# sam67_dmpac_wrap0_DMPAC_TOP_CFG_SLV_CP_INTD_CFG_INTD_CFG register map
Vendor: Texas Instruments
Peripheral module from a debugger description file (folder J722S).
Registers are 32-bit, access not given, reset 0x0 unless marked. A register's access mark holds for its fields unless they carry their own. Offsets are as the file gives them; lines under a group give offsets from that group; [hi:lo] are bit positions; {n}, {i} and the like mark numbered series; 'fields as' and 'values as' point back to an identical list; <NAME> marks a mode.

## sam67_dmpac_wrap0_DMPAC_TOP_CFG_SLV_CP_INTD_CFG_INTD_CFG (part 1 of 2)
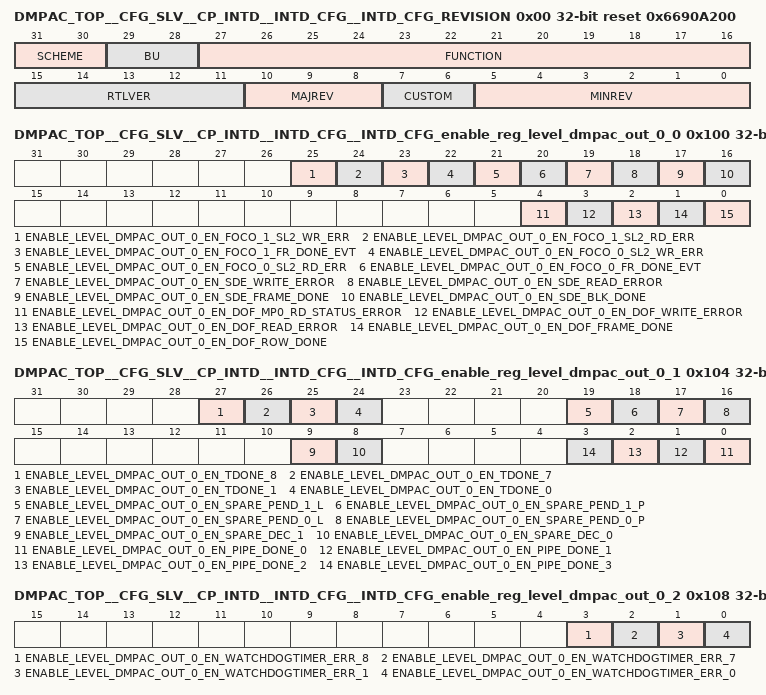
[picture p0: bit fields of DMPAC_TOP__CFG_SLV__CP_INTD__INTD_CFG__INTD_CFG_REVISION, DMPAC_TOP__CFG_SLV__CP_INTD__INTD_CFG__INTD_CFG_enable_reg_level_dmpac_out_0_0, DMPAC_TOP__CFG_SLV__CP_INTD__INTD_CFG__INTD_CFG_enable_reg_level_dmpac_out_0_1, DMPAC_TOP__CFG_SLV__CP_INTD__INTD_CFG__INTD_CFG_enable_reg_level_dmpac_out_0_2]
0x00 DMPAC_TOP__CFG_SLV__CP_INTD__INTD_CFG__INTD_CFG_REVISION ro reset 0x6690A200 — Revision Register
  [31:30] SCHEME
  [29:28] BU
  [27:16] FUNCTION — Module ID
  [15:11] RTLVER — RTL revisions
  [10:8] MAJREV — Major revision
  [7:6] CUSTOM — Custom revision
  [5:0] MINREV — Minor revision
0x10 DMPAC_TOP__CFG_SLV__CP_INTD__INTD_CFG__INTD_CFG_eoi_reg rw — End of Interrupt Register
  [7:0] EOI_VECTOR — End of Interrupt Vector
0x14 DMPAC_TOP__CFG_SLV__CP_INTD__INTD_CFG__INTD_CFG_intr_vector_reg ro — Interrupt Vector Register
  [31:0] INTR_VECTOR
0x100 DMPAC_TOP__CFG_SLV__CP_INTD__INTD_CFG__INTD_CFG_enable_reg_level_dmpac_out_0_0 — Enable Register 0
  [25] ENABLE_LEVEL_DMPAC_OUT_0_EN_FOCO_1_SL2_WR_ERR — Enable Set for level_dmpac_out_0_en_foco_1_sl2_wr_err (access R/W1TS)
  [24] ENABLE_LEVEL_DMPAC_OUT_0_EN_FOCO_1_SL2_RD_ERR — Enable Set for level_dmpac_out_0_en_foco_1_sl2_rd_err (access R/W1TS)
  [23] ENABLE_LEVEL_DMPAC_OUT_0_EN_FOCO_1_FR_DONE_EVT — Enable Set for level_dmpac_out_0_en_foco_1_fr_done_evt (access R/W1TS)
  [22] ENABLE_LEVEL_DMPAC_OUT_0_EN_FOCO_0_SL2_WR_ERR — Enable Set for level_dmpac_out_0_en_foco_0_sl2_wr_err (access R/W1TS)
  [21] ENABLE_LEVEL_DMPAC_OUT_0_EN_FOCO_0_SL2_RD_ERR — Enable Set for level_dmpac_out_0_en_foco_0_sl2_rd_err (access R/W1TS)
  [20] ENABLE_LEVEL_DMPAC_OUT_0_EN_FOCO_0_FR_DONE_EVT — Enable Set for level_dmpac_out_0_en_foco_0_fr_done_evt (access R/W1TS)
  [19] ENABLE_LEVEL_DMPAC_OUT_0_EN_SDE_WRITE_ERROR — Enable Set for level_dmpac_out_0_en_sde_write_error (access R/W1TS)
  [18] ENABLE_LEVEL_DMPAC_OUT_0_EN_SDE_READ_ERROR — Enable Set for level_dmpac_out_0_en_sde_read_error (access R/W1TS)
  [17] ENABLE_LEVEL_DMPAC_OUT_0_EN_SDE_FRAME_DONE — Enable Set for level_dmpac_out_0_en_sde_frame_done (access R/W1TS)
  [16] ENABLE_LEVEL_DMPAC_OUT_0_EN_SDE_BLK_DONE — Enable Set for level_dmpac_out_0_en_sde_blk_done (access R/W1TS)
  [4] ENABLE_LEVEL_DMPAC_OUT_0_EN_DOF_MP0_RD_STATUS_ERROR — Enable Set for level_dmpac_out_0_en_dof_mp0_rd_status_error (access R/W1TS)
  [3] ENABLE_LEVEL_DMPAC_OUT_0_EN_DOF_WRITE_ERROR — Enable Set for level_dmpac_out_0_en_dof_write_error (access R/W1TS)
  [2] ENABLE_LEVEL_DMPAC_OUT_0_EN_DOF_READ_ERROR — Enable Set for level_dmpac_out_0_en_dof_read_error (access R/W1TS)
  [1] ENABLE_LEVEL_DMPAC_OUT_0_EN_DOF_FRAME_DONE — Enable Set for level_dmpac_out_0_en_dof_frame_done (access R/W1TS)
  [0] ENABLE_LEVEL_DMPAC_OUT_0_EN_DOF_ROW_DONE — Enable Set for level_dmpac_out_0_en_dof_row_done (access R/W1TS)
0x104 DMPAC_TOP__CFG_SLV__CP_INTD__INTD_CFG__INTD_CFG_enable_reg_level_dmpac_out_0_1 — Enable Register 1
  [27] ENABLE_LEVEL_DMPAC_OUT_0_EN_TDONE_8 — Enable Set for level_dmpac_out_0_en_tdone_8 (access R/W1TS)
  [26] ENABLE_LEVEL_DMPAC_OUT_0_EN_TDONE_7 — Enable Set for level_dmpac_out_0_en_tdone_7 (access R/W1TS)
  [25] ENABLE_LEVEL_DMPAC_OUT_0_EN_TDONE_1 — Enable Set for level_dmpac_out_0_en_tdone_1 (access R/W1TS)
  [24] ENABLE_LEVEL_DMPAC_OUT_0_EN_TDONE_0 — Enable Set for level_dmpac_out_0_en_tdone_0 (access R/W1TS)
  [19] ENABLE_LEVEL_DMPAC_OUT_0_EN_SPARE_PEND_1_L — Enable Set for level_dmpac_out_0_en_spare_pend_1_l (access R/W1TS)
  [18] ENABLE_LEVEL_DMPAC_OUT_0_EN_SPARE_PEND_1_P — Enable Set for level_dmpac_out_0_en_spare_pend_1_p (access R/W1TS)
  [17] ENABLE_LEVEL_DMPAC_OUT_0_EN_SPARE_PEND_0_L — Enable Set for level_dmpac_out_0_en_spare_pend_0_l (access R/W1TS)
  [16] ENABLE_LEVEL_DMPAC_OUT_0_EN_SPARE_PEND_0_P — Enable Set for level_dmpac_out_0_en_spare_pend_0_p (access R/W1TS)
  [9] ENABLE_LEVEL_DMPAC_OUT_0_EN_SPARE_DEC_1 — Enable Set for level_dmpac_out_0_en_spare_dec_1 (access R/W1TS)
  [8] ENABLE_LEVEL_DMPAC_OUT_0_EN_SPARE_DEC_0 — Enable Set for level_dmpac_out_0_en_spare_dec_0 (access R/W1TS)
  [n] ENABLE_LEVEL_DMPAC_OUT_0_EN_PIPE_DONE_{n} (n=0..3) — Enable Set for level_dmpac_out_0_en_pipe_done_{n} (access R/W1TS)
0x108 DMPAC_TOP__CFG_SLV__CP_INTD__INTD_CFG__INTD_CFG_enable_reg_level_dmpac_out_0_2 — Enable Register 2
  [3] ENABLE_LEVEL_DMPAC_OUT_0_EN_WATCHDOGTIMER_ERR_8 — Enable Set for level_dmpac_out_0_en_watchdogtimer_err_8 (access R/W1TS)
  [2] ENABLE_LEVEL_DMPAC_OUT_0_EN_WATCHDOGTIMER_ERR_7 — Enable Set for level_dmpac_out_0_en_watchdogtimer_err_7 (access R/W1TS)
  [1] ENABLE_LEVEL_DMPAC_OUT_0_EN_WATCHDOGTIMER_ERR_1 — Enable Set for level_dmpac_out_0_en_watchdogtimer_err_1 (access R/W1TS)
  [0] ENABLE_LEVEL_DMPAC_OUT_0_EN_WATCHDOGTIMER_ERR_0 — Enable Set for level_dmpac_out_0_en_watchdogtimer_err_0 (access R/W1TS)
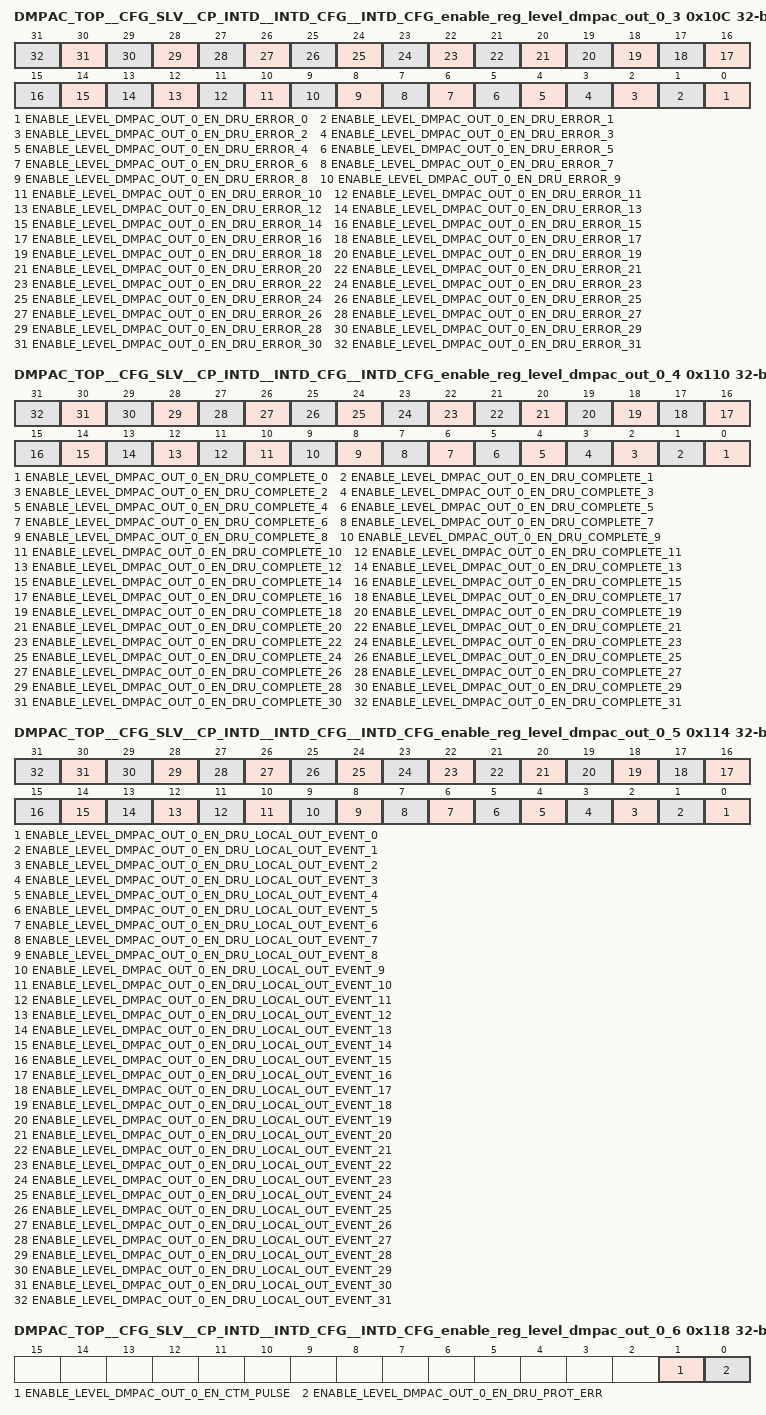
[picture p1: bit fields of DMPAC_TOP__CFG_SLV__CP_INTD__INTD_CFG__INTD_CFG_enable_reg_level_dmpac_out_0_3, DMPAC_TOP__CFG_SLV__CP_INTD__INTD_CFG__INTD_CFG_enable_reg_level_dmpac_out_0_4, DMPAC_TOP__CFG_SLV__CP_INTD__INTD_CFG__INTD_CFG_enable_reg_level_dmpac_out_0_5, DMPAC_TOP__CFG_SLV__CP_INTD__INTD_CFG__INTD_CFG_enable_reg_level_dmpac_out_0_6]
0x10C DMPAC_TOP__CFG_SLV__CP_INTD__INTD_CFG__INTD_CFG_enable_reg_level_dmpac_out_0_3 — Enable Register 3
  [n] ENABLE_LEVEL_DMPAC_OUT_0_EN_DRU_ERROR_{n} (n=0..31) — Enable Set for level_dmpac_out_0_en_dru_error_{n} (access R/W1TS)
0x110 DMPAC_TOP__CFG_SLV__CP_INTD__INTD_CFG__INTD_CFG_enable_reg_level_dmpac_out_0_4 — Enable Register 4
  [n] ENABLE_LEVEL_DMPAC_OUT_0_EN_DRU_COMPLETE_{n} (n=0..31) — Enable Set for level_dmpac_out_0_en_dru_complete_{n} (access R/W1TS)
0x114 DMPAC_TOP__CFG_SLV__CP_INTD__INTD_CFG__INTD_CFG_enable_reg_level_dmpac_out_0_5 — Enable Register 5
  [n] ENABLE_LEVEL_DMPAC_OUT_0_EN_DRU_LOCAL_OUT_EVENT_{n} (n=0..31) — Enable Set for level_dmpac_out_0_en_dru_local_out_event_{n} (access R/W1TS)
0x118 DMPAC_TOP__CFG_SLV__CP_INTD__INTD_CFG__INTD_CFG_enable_reg_level_dmpac_out_0_6 — Enable Register 6
  [1] ENABLE_LEVEL_DMPAC_OUT_0_EN_CTM_PULSE — Enable Set for level_dmpac_out_0_en_ctm_pulse (access R/W1TS)
  [0] ENABLE_LEVEL_DMPAC_OUT_0_EN_DRU_PROT_ERR — Enable Set for level_dmpac_out_0_en_dru_prot_err (access R/W1TS)
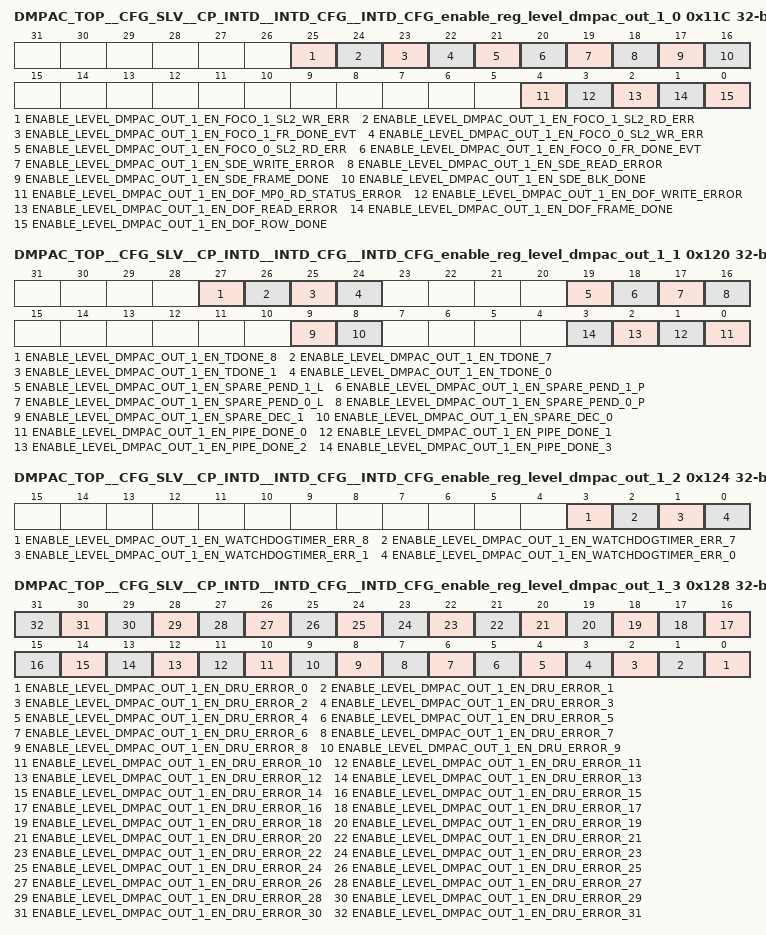
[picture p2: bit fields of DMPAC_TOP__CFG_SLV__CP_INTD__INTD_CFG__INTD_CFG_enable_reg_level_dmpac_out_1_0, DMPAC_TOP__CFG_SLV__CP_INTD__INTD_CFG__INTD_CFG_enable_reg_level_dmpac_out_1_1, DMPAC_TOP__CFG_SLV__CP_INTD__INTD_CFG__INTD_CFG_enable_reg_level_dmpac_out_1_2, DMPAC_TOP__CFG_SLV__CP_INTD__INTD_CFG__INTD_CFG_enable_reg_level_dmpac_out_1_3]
0x11C DMPAC_TOP__CFG_SLV__CP_INTD__INTD_CFG__INTD_CFG_enable_reg_level_dmpac_out_1_0 — Enable Register 7
  [25] ENABLE_LEVEL_DMPAC_OUT_1_EN_FOCO_1_SL2_WR_ERR — Enable Set for level_dmpac_out_1_en_foco_1_sl2_wr_err (access R/W1TS)
  [24] ENABLE_LEVEL_DMPAC_OUT_1_EN_FOCO_1_SL2_RD_ERR — Enable Set for level_dmpac_out_1_en_foco_1_sl2_rd_err (access R/W1TS)
  [23] ENABLE_LEVEL_DMPAC_OUT_1_EN_FOCO_1_FR_DONE_EVT — Enable Set for level_dmpac_out_1_en_foco_1_fr_done_evt (access R/W1TS)
  [22] ENABLE_LEVEL_DMPAC_OUT_1_EN_FOCO_0_SL2_WR_ERR — Enable Set for level_dmpac_out_1_en_foco_0_sl2_wr_err (access R/W1TS)
  [21] ENABLE_LEVEL_DMPAC_OUT_1_EN_FOCO_0_SL2_RD_ERR — Enable Set for level_dmpac_out_1_en_foco_0_sl2_rd_err (access R/W1TS)
  [20] ENABLE_LEVEL_DMPAC_OUT_1_EN_FOCO_0_FR_DONE_EVT — Enable Set for level_dmpac_out_1_en_foco_0_fr_done_evt (access R/W1TS)
  [19] ENABLE_LEVEL_DMPAC_OUT_1_EN_SDE_WRITE_ERROR — Enable Set for level_dmpac_out_1_en_sde_write_error (access R/W1TS)
  [18] ENABLE_LEVEL_DMPAC_OUT_1_EN_SDE_READ_ERROR — Enable Set for level_dmpac_out_1_en_sde_read_error (access R/W1TS)
  [17] ENABLE_LEVEL_DMPAC_OUT_1_EN_SDE_FRAME_DONE — Enable Set for level_dmpac_out_1_en_sde_frame_done (access R/W1TS)
  [16] ENABLE_LEVEL_DMPAC_OUT_1_EN_SDE_BLK_DONE — Enable Set for level_dmpac_out_1_en_sde_blk_done (access R/W1TS)
  [4] ENABLE_LEVEL_DMPAC_OUT_1_EN_DOF_MP0_RD_STATUS_ERROR — Enable Set for level_dmpac_out_1_en_dof_mp0_rd_status_error (access R/W1TS)
  [3] ENABLE_LEVEL_DMPAC_OUT_1_EN_DOF_WRITE_ERROR — Enable Set for level_dmpac_out_1_en_dof_write_error (access R/W1TS)
  [2] ENABLE_LEVEL_DMPAC_OUT_1_EN_DOF_READ_ERROR — Enable Set for level_dmpac_out_1_en_dof_read_error (access R/W1TS)
  [1] ENABLE_LEVEL_DMPAC_OUT_1_EN_DOF_FRAME_DONE — Enable Set for level_dmpac_out_1_en_dof_frame_done (access R/W1TS)
  [0] ENABLE_LEVEL_DMPAC_OUT_1_EN_DOF_ROW_DONE — Enable Set for level_dmpac_out_1_en_dof_row_done (access R/W1TS)
0x120 DMPAC_TOP__CFG_SLV__CP_INTD__INTD_CFG__INTD_CFG_enable_reg_level_dmpac_out_1_1 — Enable Register 8
  [27] ENABLE_LEVEL_DMPAC_OUT_1_EN_TDONE_8 — Enable Set for level_dmpac_out_1_en_tdone_8 (access R/W1TS)
  [26] ENABLE_LEVEL_DMPAC_OUT_1_EN_TDONE_7 — Enable Set for level_dmpac_out_1_en_tdone_7 (access R/W1TS)
  [25] ENABLE_LEVEL_DMPAC_OUT_1_EN_TDONE_1 — Enable Set for level_dmpac_out_1_en_tdone_1 (access R/W1TS)
  [24] ENABLE_LEVEL_DMPAC_OUT_1_EN_TDONE_0 — Enable Set for level_dmpac_out_1_en_tdone_0 (access R/W1TS)
  [19] ENABLE_LEVEL_DMPAC_OUT_1_EN_SPARE_PEND_1_L — Enable Set for level_dmpac_out_1_en_spare_pend_1_l (access R/W1TS)
  [18] ENABLE_LEVEL_DMPAC_OUT_1_EN_SPARE_PEND_1_P — Enable Set for level_dmpac_out_1_en_spare_pend_1_p (access R/W1TS)
  [17] ENABLE_LEVEL_DMPAC_OUT_1_EN_SPARE_PEND_0_L — Enable Set for level_dmpac_out_1_en_spare_pend_0_l (access R/W1TS)
  [16] ENABLE_LEVEL_DMPAC_OUT_1_EN_SPARE_PEND_0_P — Enable Set for level_dmpac_out_1_en_spare_pend_0_p (access R/W1TS)
  [9] ENABLE_LEVEL_DMPAC_OUT_1_EN_SPARE_DEC_1 — Enable Set for level_dmpac_out_1_en_spare_dec_1 (access R/W1TS)
  [8] ENABLE_LEVEL_DMPAC_OUT_1_EN_SPARE_DEC_0 — Enable Set for level_dmpac_out_1_en_spare_dec_0 (access R/W1TS)
  [n] ENABLE_LEVEL_DMPAC_OUT_1_EN_PIPE_DONE_{n} (n=0..3) — Enable Set for level_dmpac_out_1_en_pipe_done_{n} (access R/W1TS)
0x124 DMPAC_TOP__CFG_SLV__CP_INTD__INTD_CFG__INTD_CFG_enable_reg_level_dmpac_out_1_2 — Enable Register 9
  [3] ENABLE_LEVEL_DMPAC_OUT_1_EN_WATCHDOGTIMER_ERR_8 — Enable Set for level_dmpac_out_1_en_watchdogtimer_err_8 (access R/W1TS)
  [2] ENABLE_LEVEL_DMPAC_OUT_1_EN_WATCHDOGTIMER_ERR_7 — Enable Set for level_dmpac_out_1_en_watchdogtimer_err_7 (access R/W1TS)
  [1] ENABLE_LEVEL_DMPAC_OUT_1_EN_WATCHDOGTIMER_ERR_1 — Enable Set for level_dmpac_out_1_en_watchdogtimer_err_1 (access R/W1TS)
  [0] ENABLE_LEVEL_DMPAC_OUT_1_EN_WATCHDOGTIMER_ERR_0 — Enable Set for level_dmpac_out_1_en_watchdogtimer_err_0 (access R/W1TS)
0x128 DMPAC_TOP__CFG_SLV__CP_INTD__INTD_CFG__INTD_CFG_enable_reg_level_dmpac_out_1_3 — Enable Register 10
  [n] ENABLE_LEVEL_DMPAC_OUT_1_EN_DRU_ERROR_{n} (n=0..31) — Enable Set for level_dmpac_out_1_en_dru_error_{n} (access R/W1TS)
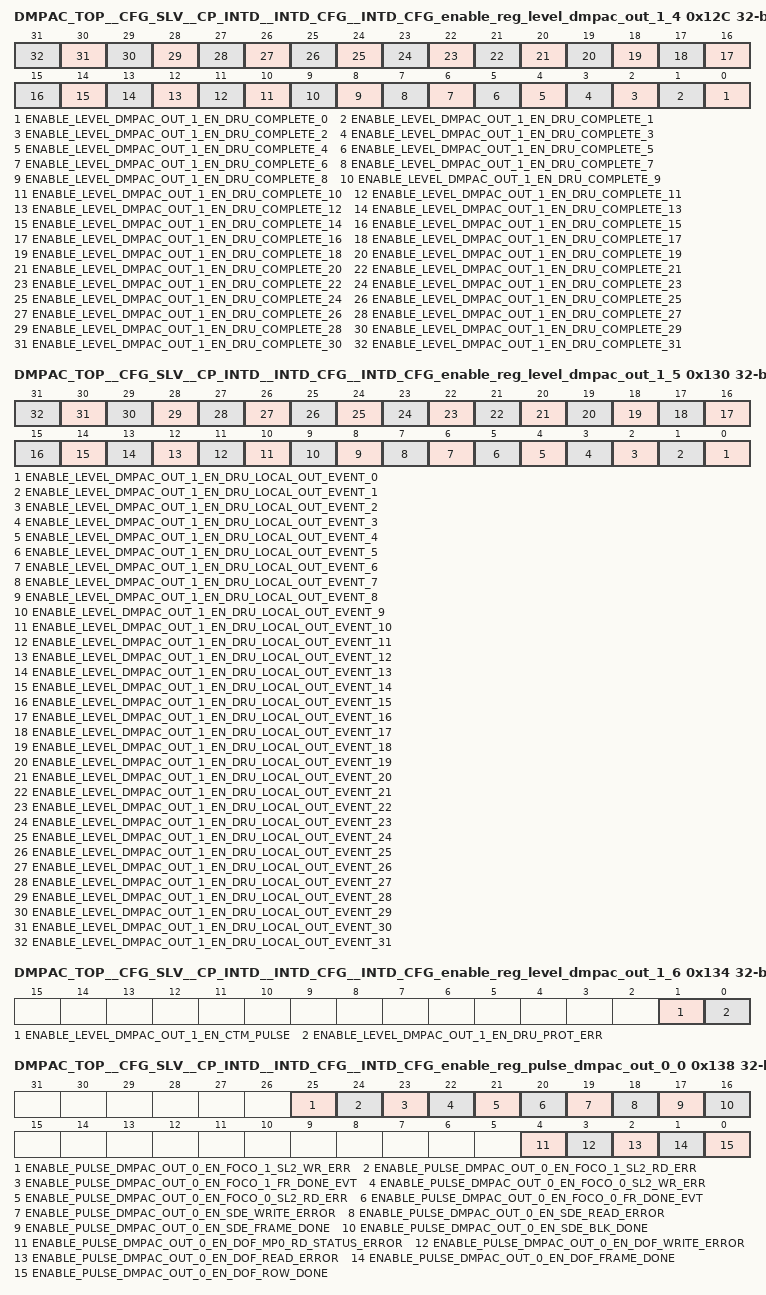
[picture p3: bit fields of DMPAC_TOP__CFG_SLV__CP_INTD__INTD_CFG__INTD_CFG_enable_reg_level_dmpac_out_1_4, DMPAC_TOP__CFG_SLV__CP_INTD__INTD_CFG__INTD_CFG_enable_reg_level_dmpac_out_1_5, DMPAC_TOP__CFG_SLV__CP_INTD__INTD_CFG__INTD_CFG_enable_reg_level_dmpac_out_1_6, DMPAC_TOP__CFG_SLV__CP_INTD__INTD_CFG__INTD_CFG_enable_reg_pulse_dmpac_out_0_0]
0x12C DMPAC_TOP__CFG_SLV__CP_INTD__INTD_CFG__INTD_CFG_enable_reg_level_dmpac_out_1_4 — Enable Register 11
  [n] ENABLE_LEVEL_DMPAC_OUT_1_EN_DRU_COMPLETE_{n} (n=0..31) — Enable Set for level_dmpac_out_1_en_dru_complete_{n} (access R/W1TS)
0x130 DMPAC_TOP__CFG_SLV__CP_INTD__INTD_CFG__INTD_CFG_enable_reg_level_dmpac_out_1_5 — Enable Register 12
  [n] ENABLE_LEVEL_DMPAC_OUT_1_EN_DRU_LOCAL_OUT_EVENT_{n} (n=0..31) — Enable Set for level_dmpac_out_1_en_dru_local_out_event_{n} (access R/W1TS)
0x134 DMPAC_TOP__CFG_SLV__CP_INTD__INTD_CFG__INTD_CFG_enable_reg_level_dmpac_out_1_6 — Enable Register 13
  [1] ENABLE_LEVEL_DMPAC_OUT_1_EN_CTM_PULSE — Enable Set for level_dmpac_out_1_en_ctm_pulse (access R/W1TS)
  [0] ENABLE_LEVEL_DMPAC_OUT_1_EN_DRU_PROT_ERR — Enable Set for level_dmpac_out_1_en_dru_prot_err (access R/W1TS)
0x138 DMPAC_TOP__CFG_SLV__CP_INTD__INTD_CFG__INTD_CFG_enable_reg_pulse_dmpac_out_0_0 — Enable Register 14
  [25] ENABLE_PULSE_DMPAC_OUT_0_EN_FOCO_1_SL2_WR_ERR — Enable Set for pulse_dmpac_out_0_en_foco_1_sl2_wr_err (access R/W1TS)
  [24] ENABLE_PULSE_DMPAC_OUT_0_EN_FOCO_1_SL2_RD_ERR — Enable Set for pulse_dmpac_out_0_en_foco_1_sl2_rd_err (access R/W1TS)
  [23] ENABLE_PULSE_DMPAC_OUT_0_EN_FOCO_1_FR_DONE_EVT — Enable Set for pulse_dmpac_out_0_en_foco_1_fr_done_evt (access R/W1TS)
  [22] ENABLE_PULSE_DMPAC_OUT_0_EN_FOCO_0_SL2_WR_ERR — Enable Set for pulse_dmpac_out_0_en_foco_0_sl2_wr_err (access R/W1TS)
  [21] ENABLE_PULSE_DMPAC_OUT_0_EN_FOCO_0_SL2_RD_ERR — Enable Set for pulse_dmpac_out_0_en_foco_0_sl2_rd_err (access R/W1TS)
  [20] ENABLE_PULSE_DMPAC_OUT_0_EN_FOCO_0_FR_DONE_EVT — Enable Set for pulse_dmpac_out_0_en_foco_0_fr_done_evt (access R/W1TS)
  [19] ENABLE_PULSE_DMPAC_OUT_0_EN_SDE_WRITE_ERROR — Enable Set for pulse_dmpac_out_0_en_sde_write_error (access R/W1TS)
  [18] ENABLE_PULSE_DMPAC_OUT_0_EN_SDE_READ_ERROR — Enable Set for pulse_dmpac_out_0_en_sde_read_error (access R/W1TS)
  [17] ENABLE_PULSE_DMPAC_OUT_0_EN_SDE_FRAME_DONE — Enable Set for pulse_dmpac_out_0_en_sde_frame_done (access R/W1TS)
  [16] ENABLE_PULSE_DMPAC_OUT_0_EN_SDE_BLK_DONE — Enable Set for pulse_dmpac_out_0_en_sde_blk_done (access R/W1TS)
  [4] ENABLE_PULSE_DMPAC_OUT_0_EN_DOF_MP0_RD_STATUS_ERROR — Enable Set for pulse_dmpac_out_0_en_dof_mp0_rd_status_error (access R/W1TS)
  [3] ENABLE_PULSE_DMPAC_OUT_0_EN_DOF_WRITE_ERROR — Enable Set for pulse_dmpac_out_0_en_dof_write_error (access R/W1TS)
  [2] ENABLE_PULSE_DMPAC_OUT_0_EN_DOF_READ_ERROR — Enable Set for pulse_dmpac_out_0_en_dof_read_error (access R/W1TS)
  [1] ENABLE_PULSE_DMPAC_OUT_0_EN_DOF_FRAME_DONE — Enable Set for pulse_dmpac_out_0_en_dof_frame_done (access R/W1TS)
  [0] ENABLE_PULSE_DMPAC_OUT_0_EN_DOF_ROW_DONE — Enable Set for pulse_dmpac_out_0_en_dof_row_done (access R/W1TS)
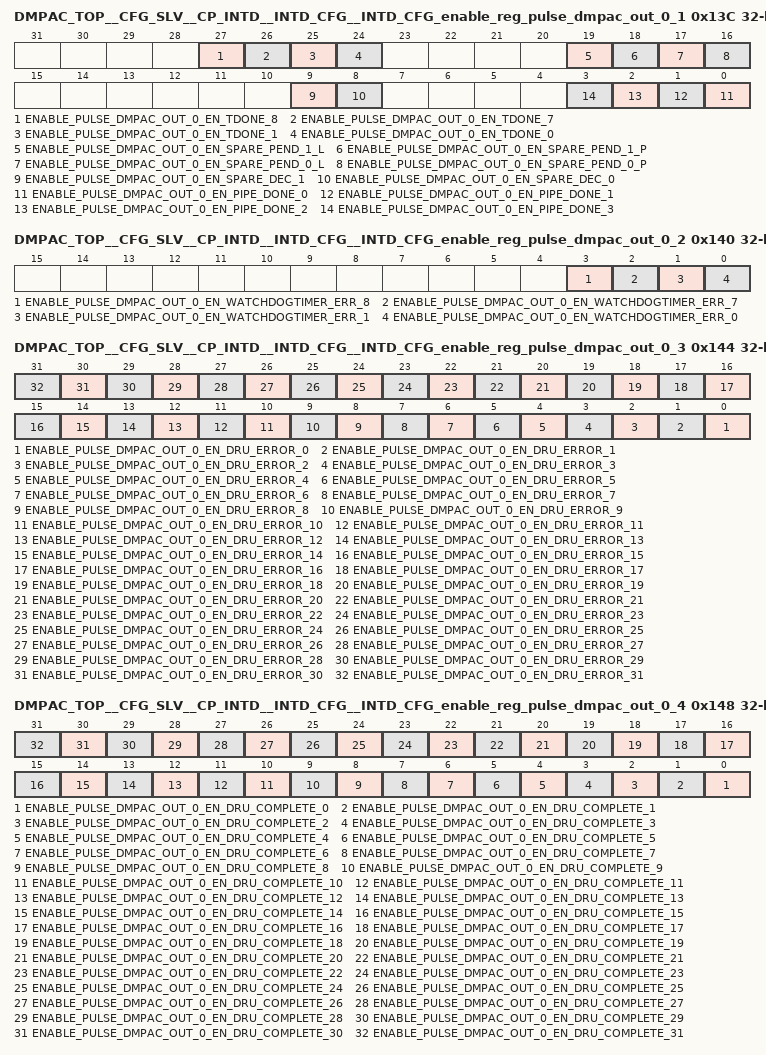
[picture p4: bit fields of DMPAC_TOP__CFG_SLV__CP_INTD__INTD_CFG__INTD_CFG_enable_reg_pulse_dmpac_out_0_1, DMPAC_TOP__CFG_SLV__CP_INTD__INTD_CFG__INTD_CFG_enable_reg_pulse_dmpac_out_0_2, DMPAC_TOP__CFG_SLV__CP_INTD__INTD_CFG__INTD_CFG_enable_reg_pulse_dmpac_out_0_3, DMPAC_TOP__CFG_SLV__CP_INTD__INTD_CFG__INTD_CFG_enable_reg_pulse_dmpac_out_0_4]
0x13C DMPAC_TOP__CFG_SLV__CP_INTD__INTD_CFG__INTD_CFG_enable_reg_pulse_dmpac_out_0_1 — Enable Register 15
  [27] ENABLE_PULSE_DMPAC_OUT_0_EN_TDONE_8 — Enable Set for pulse_dmpac_out_0_en_tdone_8 (access R/W1TS)
  [26] ENABLE_PULSE_DMPAC_OUT_0_EN_TDONE_7 — Enable Set for pulse_dmpac_out_0_en_tdone_7 (access R/W1TS)
  [25] ENABLE_PULSE_DMPAC_OUT_0_EN_TDONE_1 — Enable Set for pulse_dmpac_out_0_en_tdone_1 (access R/W1TS)
  [24] ENABLE_PULSE_DMPAC_OUT_0_EN_TDONE_0 — Enable Set for pulse_dmpac_out_0_en_tdone_0 (access R/W1TS)
  [19] ENABLE_PULSE_DMPAC_OUT_0_EN_SPARE_PEND_1_L — Enable Set for pulse_dmpac_out_0_en_spare_pend_1_l (access R/W1TS)
  [18] ENABLE_PULSE_DMPAC_OUT_0_EN_SPARE_PEND_1_P — Enable Set for pulse_dmpac_out_0_en_spare_pend_1_p (access R/W1TS)
  [17] ENABLE_PULSE_DMPAC_OUT_0_EN_SPARE_PEND_0_L — Enable Set for pulse_dmpac_out_0_en_spare_pend_0_l (access R/W1TS)
  [16] ENABLE_PULSE_DMPAC_OUT_0_EN_SPARE_PEND_0_P — Enable Set for pulse_dmpac_out_0_en_spare_pend_0_p (access R/W1TS)
  [9] ENABLE_PULSE_DMPAC_OUT_0_EN_SPARE_DEC_1 — Enable Set for pulse_dmpac_out_0_en_spare_dec_1 (access R/W1TS)
  [8] ENABLE_PULSE_DMPAC_OUT_0_EN_SPARE_DEC_0 — Enable Set for pulse_dmpac_out_0_en_spare_dec_0 (access R/W1TS)
  [n] ENABLE_PULSE_DMPAC_OUT_0_EN_PIPE_DONE_{n} (n=0..3) — Enable Set for pulse_dmpac_out_0_en_pipe_done_{n} (access R/W1TS)
0x140 DMPAC_TOP__CFG_SLV__CP_INTD__INTD_CFG__INTD_CFG_enable_reg_pulse_dmpac_out_0_2 — Enable Register 16
  [3] ENABLE_PULSE_DMPAC_OUT_0_EN_WATCHDOGTIMER_ERR_8 — Enable Set for pulse_dmpac_out_0_en_watchdogtimer_err_8 (access R/W1TS)
  [2] ENABLE_PULSE_DMPAC_OUT_0_EN_WATCHDOGTIMER_ERR_7 — Enable Set for pulse_dmpac_out_0_en_watchdogtimer_err_7 (access R/W1TS)
  [1] ENABLE_PULSE_DMPAC_OUT_0_EN_WATCHDOGTIMER_ERR_1 — Enable Set for pulse_dmpac_out_0_en_watchdogtimer_err_1 (access R/W1TS)
  [0] ENABLE_PULSE_DMPAC_OUT_0_EN_WATCHDOGTIMER_ERR_0 — Enable Set for pulse_dmpac_out_0_en_watchdogtimer_err_0 (access R/W1TS)
0x144 DMPAC_TOP__CFG_SLV__CP_INTD__INTD_CFG__INTD_CFG_enable_reg_pulse_dmpac_out_0_3 — Enable Register 17
  [n] ENABLE_PULSE_DMPAC_OUT_0_EN_DRU_ERROR_{n} (n=0..31) — Enable Set for pulse_dmpac_out_0_en_dru_error_{n} (access R/W1TS)
0x148 DMPAC_TOP__CFG_SLV__CP_INTD__INTD_CFG__INTD_CFG_enable_reg_pulse_dmpac_out_0_4 — Enable Register 18
  [n] ENABLE_PULSE_DMPAC_OUT_0_EN_DRU_COMPLETE_{n} (n=0..31) — Enable Set for pulse_dmpac_out_0_en_dru_complete_{n} (access R/W1TS)
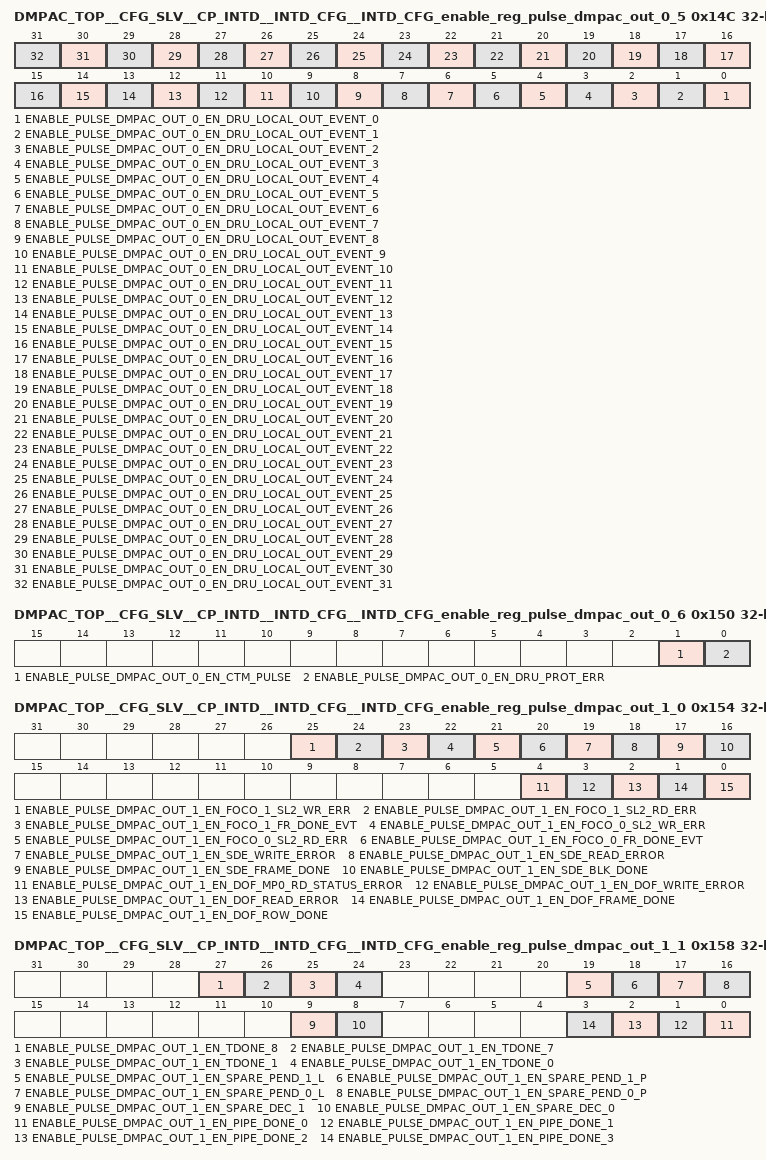
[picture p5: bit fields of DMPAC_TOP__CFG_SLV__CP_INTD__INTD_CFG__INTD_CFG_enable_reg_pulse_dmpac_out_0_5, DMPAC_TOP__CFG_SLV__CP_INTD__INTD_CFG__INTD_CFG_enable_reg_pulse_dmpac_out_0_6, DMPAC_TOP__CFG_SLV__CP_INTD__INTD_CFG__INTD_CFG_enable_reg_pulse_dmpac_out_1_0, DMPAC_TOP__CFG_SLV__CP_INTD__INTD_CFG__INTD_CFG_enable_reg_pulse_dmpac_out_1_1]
0x14C DMPAC_TOP__CFG_SLV__CP_INTD__INTD_CFG__INTD_CFG_enable_reg_pulse_dmpac_out_0_5 — Enable Register 19
  [n] ENABLE_PULSE_DMPAC_OUT_0_EN_DRU_LOCAL_OUT_EVENT_{n} (n=0..31) — Enable Set for pulse_dmpac_out_0_en_dru_local_out_event_{n} (access R/W1TS)
0x150 DMPAC_TOP__CFG_SLV__CP_INTD__INTD_CFG__INTD_CFG_enable_reg_pulse_dmpac_out_0_6 — Enable Register 20
  [1] ENABLE_PULSE_DMPAC_OUT_0_EN_CTM_PULSE — Enable Set for pulse_dmpac_out_0_en_ctm_pulse (access R/W1TS)
  [0] ENABLE_PULSE_DMPAC_OUT_0_EN_DRU_PROT_ERR — Enable Set for pulse_dmpac_out_0_en_dru_prot_err (access R/W1TS)
0x154 DMPAC_TOP__CFG_SLV__CP_INTD__INTD_CFG__INTD_CFG_enable_reg_pulse_dmpac_out_1_0 — Enable Register 21
  [25] ENABLE_PULSE_DMPAC_OUT_1_EN_FOCO_1_SL2_WR_ERR — Enable Set for pulse_dmpac_out_1_en_foco_1_sl2_wr_err (access R/W1TS)
  [24] ENABLE_PULSE_DMPAC_OUT_1_EN_FOCO_1_SL2_RD_ERR — Enable Set for pulse_dmpac_out_1_en_foco_1_sl2_rd_err (access R/W1TS)
  [23] ENABLE_PULSE_DMPAC_OUT_1_EN_FOCO_1_FR_DONE_EVT — Enable Set for pulse_dmpac_out_1_en_foco_1_fr_done_evt (access R/W1TS)
  [22] ENABLE_PULSE_DMPAC_OUT_1_EN_FOCO_0_SL2_WR_ERR — Enable Set for pulse_dmpac_out_1_en_foco_0_sl2_wr_err (access R/W1TS)
  [21] ENABLE_PULSE_DMPAC_OUT_1_EN_FOCO_0_SL2_RD_ERR — Enable Set for pulse_dmpac_out_1_en_foco_0_sl2_rd_err (access R/W1TS)
  [20] ENABLE_PULSE_DMPAC_OUT_1_EN_FOCO_0_FR_DONE_EVT — Enable Set for pulse_dmpac_out_1_en_foco_0_fr_done_evt (access R/W1TS)
  [19] ENABLE_PULSE_DMPAC_OUT_1_EN_SDE_WRITE_ERROR — Enable Set for pulse_dmpac_out_1_en_sde_write_error (access R/W1TS)
  [18] ENABLE_PULSE_DMPAC_OUT_1_EN_SDE_READ_ERROR — Enable Set for pulse_dmpac_out_1_en_sde_read_error (access R/W1TS)
  [17] ENABLE_PULSE_DMPAC_OUT_1_EN_SDE_FRAME_DONE — Enable Set for pulse_dmpac_out_1_en_sde_frame_done (access R/W1TS)
  [16] ENABLE_PULSE_DMPAC_OUT_1_EN_SDE_BLK_DONE — Enable Set for pulse_dmpac_out_1_en_sde_blk_done (access R/W1TS)
  [4] ENABLE_PULSE_DMPAC_OUT_1_EN_DOF_MP0_RD_STATUS_ERROR — Enable Set for pulse_dmpac_out_1_en_dof_mp0_rd_status_error (access R/W1TS)
  [3] ENABLE_PULSE_DMPAC_OUT_1_EN_DOF_WRITE_ERROR — Enable Set for pulse_dmpac_out_1_en_dof_write_error (access R/W1TS)
  [2] ENABLE_PULSE_DMPAC_OUT_1_EN_DOF_READ_ERROR — Enable Set for pulse_dmpac_out_1_en_dof_read_error (access R/W1TS)
  [1] ENABLE_PULSE_DMPAC_OUT_1_EN_DOF_FRAME_DONE — Enable Set for pulse_dmpac_out_1_en_dof_frame_done (access R/W1TS)
  [0] ENABLE_PULSE_DMPAC_OUT_1_EN_DOF_ROW_DONE — Enable Set for pulse_dmpac_out_1_en_dof_row_done (access R/W1TS)
0x158 DMPAC_TOP__CFG_SLV__CP_INTD__INTD_CFG__INTD_CFG_enable_reg_pulse_dmpac_out_1_1 — Enable Register 22
  [27] ENABLE_PULSE_DMPAC_OUT_1_EN_TDONE_8 — Enable Set for pulse_dmpac_out_1_en_tdone_8 (access R/W1TS)
  [26] ENABLE_PULSE_DMPAC_OUT_1_EN_TDONE_7 — Enable Set for pulse_dmpac_out_1_en_tdone_7 (access R/W1TS)
  [25] ENABLE_PULSE_DMPAC_OUT_1_EN_TDONE_1 — Enable Set for pulse_dmpac_out_1_en_tdone_1 (access R/W1TS)
  [24] ENABLE_PULSE_DMPAC_OUT_1_EN_TDONE_0 — Enable Set for pulse_dmpac_out_1_en_tdone_0 (access R/W1TS)
  [19] ENABLE_PULSE_DMPAC_OUT_1_EN_SPARE_PEND_1_L — Enable Set for pulse_dmpac_out_1_en_spare_pend_1_l (access R/W1TS)
  [18] ENABLE_PULSE_DMPAC_OUT_1_EN_SPARE_PEND_1_P — Enable Set for pulse_dmpac_out_1_en_spare_pend_1_p (access R/W1TS)
  [17] ENABLE_PULSE_DMPAC_OUT_1_EN_SPARE_PEND_0_L — Enable Set for pulse_dmpac_out_1_en_spare_pend_0_l (access R/W1TS)
  [16] ENABLE_PULSE_DMPAC_OUT_1_EN_SPARE_PEND_0_P — Enable Set for pulse_dmpac_out_1_en_spare_pend_0_p (access R/W1TS)
  [9] ENABLE_PULSE_DMPAC_OUT_1_EN_SPARE_DEC_1 — Enable Set for pulse_dmpac_out_1_en_spare_dec_1 (access R/W1TS)
  [8] ENABLE_PULSE_DMPAC_OUT_1_EN_SPARE_DEC_0 — Enable Set for pulse_dmpac_out_1_en_spare_dec_0 (access R/W1TS)
  [n] ENABLE_PULSE_DMPAC_OUT_1_EN_PIPE_DONE_{n} (n=0..3) — Enable Set for pulse_dmpac_out_1_en_pipe_done_{n} (access R/W1TS)
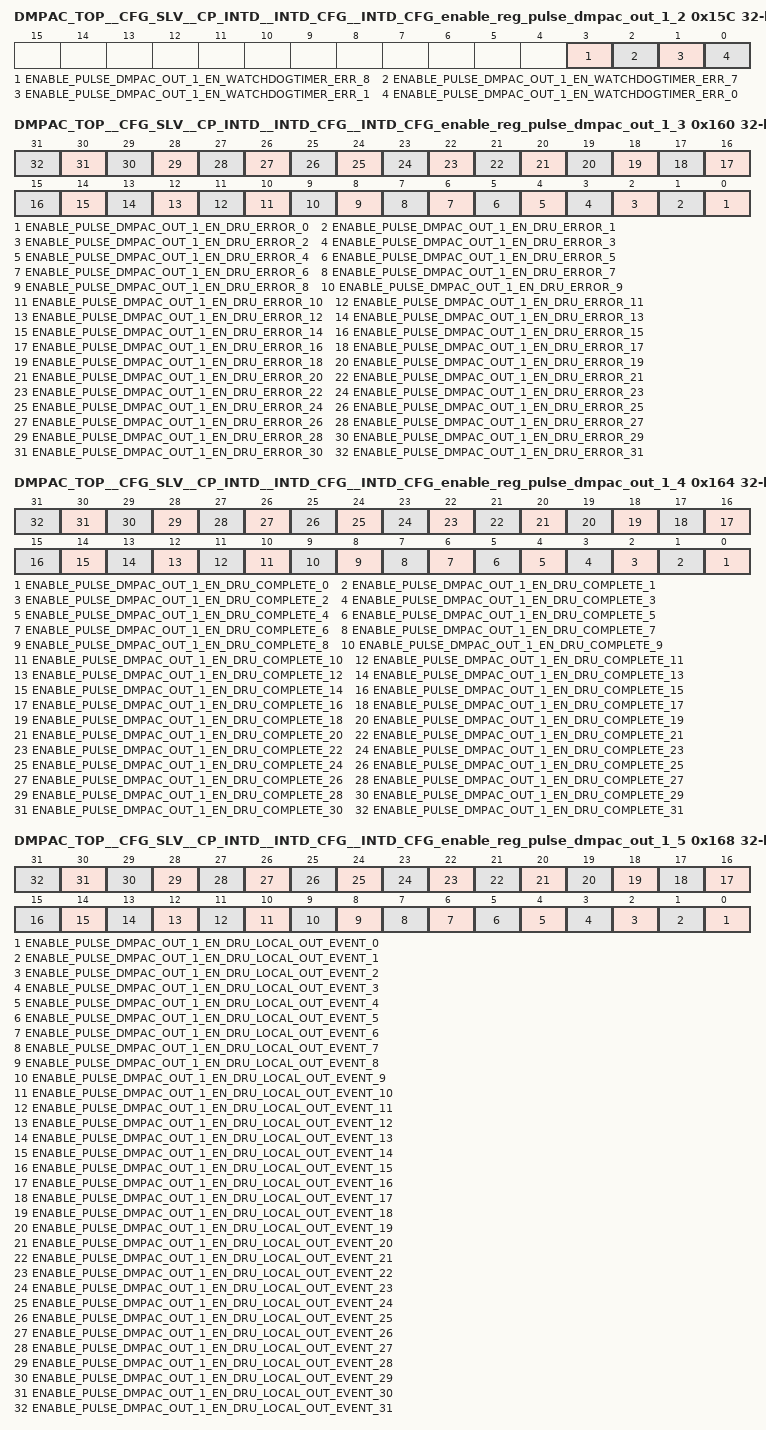
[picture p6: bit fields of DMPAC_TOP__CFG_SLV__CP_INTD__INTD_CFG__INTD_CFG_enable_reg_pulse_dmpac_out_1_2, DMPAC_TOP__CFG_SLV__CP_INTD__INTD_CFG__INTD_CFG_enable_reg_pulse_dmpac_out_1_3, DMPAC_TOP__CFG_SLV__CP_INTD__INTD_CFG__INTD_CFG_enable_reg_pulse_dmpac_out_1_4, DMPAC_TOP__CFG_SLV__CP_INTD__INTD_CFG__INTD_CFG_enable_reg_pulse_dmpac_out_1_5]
0x15C DMPAC_TOP__CFG_SLV__CP_INTD__INTD_CFG__INTD_CFG_enable_reg_pulse_dmpac_out_1_2 — Enable Register 23
  [3] ENABLE_PULSE_DMPAC_OUT_1_EN_WATCHDOGTIMER_ERR_8 — Enable Set for pulse_dmpac_out_1_en_watchdogtimer_err_8 (access R/W1TS)
  [2] ENABLE_PULSE_DMPAC_OUT_1_EN_WATCHDOGTIMER_ERR_7 — Enable Set for pulse_dmpac_out_1_en_watchdogtimer_err_7 (access R/W1TS)
  [1] ENABLE_PULSE_DMPAC_OUT_1_EN_WATCHDOGTIMER_ERR_1 — Enable Set for pulse_dmpac_out_1_en_watchdogtimer_err_1 (access R/W1TS)
  [0] ENABLE_PULSE_DMPAC_OUT_1_EN_WATCHDOGTIMER_ERR_0 — Enable Set for pulse_dmpac_out_1_en_watchdogtimer_err_0 (access R/W1TS)
0x160 DMPAC_TOP__CFG_SLV__CP_INTD__INTD_CFG__INTD_CFG_enable_reg_pulse_dmpac_out_1_3 — Enable Register 24
  [n] ENABLE_PULSE_DMPAC_OUT_1_EN_DRU_ERROR_{n} (n=0..31) — Enable Set for pulse_dmpac_out_1_en_dru_error_{n} (access R/W1TS)
0x164 DMPAC_TOP__CFG_SLV__CP_INTD__INTD_CFG__INTD_CFG_enable_reg_pulse_dmpac_out_1_4 — Enable Register 25
  [n] ENABLE_PULSE_DMPAC_OUT_1_EN_DRU_COMPLETE_{n} (n=0..31) — Enable Set for pulse_dmpac_out_1_en_dru_complete_{n} (access R/W1TS)
0x168 DMPAC_TOP__CFG_SLV__CP_INTD__INTD_CFG__INTD_CFG_enable_reg_pulse_dmpac_out_1_5 — Enable Register 26
  [n] ENABLE_PULSE_DMPAC_OUT_1_EN_DRU_LOCAL_OUT_EVENT_{n} (n=0..31) — Enable Set for pulse_dmpac_out_1_en_dru_local_out_event_{n} (access R/W1TS)
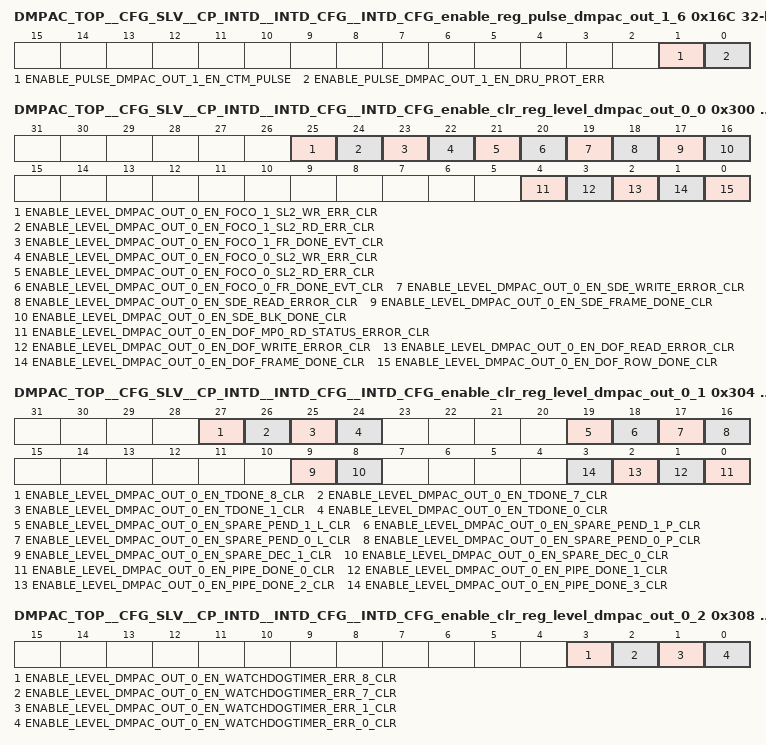
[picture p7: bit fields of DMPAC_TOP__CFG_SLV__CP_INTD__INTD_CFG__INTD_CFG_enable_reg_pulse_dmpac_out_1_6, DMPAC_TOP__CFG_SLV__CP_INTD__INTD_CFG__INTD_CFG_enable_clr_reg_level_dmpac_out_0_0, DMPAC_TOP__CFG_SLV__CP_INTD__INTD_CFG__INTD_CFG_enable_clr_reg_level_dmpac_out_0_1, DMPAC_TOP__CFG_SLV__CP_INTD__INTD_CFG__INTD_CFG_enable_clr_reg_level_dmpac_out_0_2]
0x16C DMPAC_TOP__CFG_SLV__CP_INTD__INTD_CFG__INTD_CFG_enable_reg_pulse_dmpac_out_1_6 — Enable Register 27
  [1] ENABLE_PULSE_DMPAC_OUT_1_EN_CTM_PULSE — Enable Set for pulse_dmpac_out_1_en_ctm_pulse (access R/W1TS)
  [0] ENABLE_PULSE_DMPAC_OUT_1_EN_DRU_PROT_ERR — Enable Set for pulse_dmpac_out_1_en_dru_prot_err (access R/W1TS)
0x300 DMPAC_TOP__CFG_SLV__CP_INTD__INTD_CFG__INTD_CFG_enable_clr_reg_level_dmpac_out_0_0 — Enable Clear Register 0
  [25] ENABLE_LEVEL_DMPAC_OUT_0_EN_FOCO_1_SL2_WR_ERR_CLR — Enable Clear for level_dmpac_out_0_en_foco_1_sl2_wr_err (access R/W1TC)
  [24] ENABLE_LEVEL_DMPAC_OUT_0_EN_FOCO_1_SL2_RD_ERR_CLR — Enable Clear for level_dmpac_out_0_en_foco_1_sl2_rd_err (access R/W1TC)
  [23] ENABLE_LEVEL_DMPAC_OUT_0_EN_FOCO_1_FR_DONE_EVT_CLR — Enable Clear for level_dmpac_out_0_en_foco_1_fr_done_evt (access R/W1TC)
  [22] ENABLE_LEVEL_DMPAC_OUT_0_EN_FOCO_0_SL2_WR_ERR_CLR — Enable Clear for level_dmpac_out_0_en_foco_0_sl2_wr_err (access R/W1TC)
  [21] ENABLE_LEVEL_DMPAC_OUT_0_EN_FOCO_0_SL2_RD_ERR_CLR — Enable Clear for level_dmpac_out_0_en_foco_0_sl2_rd_err (access R/W1TC)
  [20] ENABLE_LEVEL_DMPAC_OUT_0_EN_FOCO_0_FR_DONE_EVT_CLR — Enable Clear for level_dmpac_out_0_en_foco_0_fr_done_evt (access R/W1TC)
  [19] ENABLE_LEVEL_DMPAC_OUT_0_EN_SDE_WRITE_ERROR_CLR — Enable Clear for level_dmpac_out_0_en_sde_write_error (access R/W1TC)
  [18] ENABLE_LEVEL_DMPAC_OUT_0_EN_SDE_READ_ERROR_CLR — Enable Clear for level_dmpac_out_0_en_sde_read_error (access R/W1TC)
  [17] ENABLE_LEVEL_DMPAC_OUT_0_EN_SDE_FRAME_DONE_CLR — Enable Clear for level_dmpac_out_0_en_sde_frame_done (access R/W1TC)
  [16] ENABLE_LEVEL_DMPAC_OUT_0_EN_SDE_BLK_DONE_CLR — Enable Clear for level_dmpac_out_0_en_sde_blk_done (access R/W1TC)
  [4] ENABLE_LEVEL_DMPAC_OUT_0_EN_DOF_MP0_RD_STATUS_ERROR_CLR — Enable Clear for level_dmpac_out_0_en_dof_mp0_rd_status_error (access R/W1TC)
  [3] ENABLE_LEVEL_DMPAC_OUT_0_EN_DOF_WRITE_ERROR_CLR — Enable Clear for level_dmpac_out_0_en_dof_write_error (access R/W1TC)
  [2] ENABLE_LEVEL_DMPAC_OUT_0_EN_DOF_READ_ERROR_CLR — Enable Clear for level_dmpac_out_0_en_dof_read_error (access R/W1TC)
  [1] ENABLE_LEVEL_DMPAC_OUT_0_EN_DOF_FRAME_DONE_CLR — Enable Clear for level_dmpac_out_0_en_dof_frame_done (access R/W1TC)
  [0] ENABLE_LEVEL_DMPAC_OUT_0_EN_DOF_ROW_DONE_CLR — Enable Clear for level_dmpac_out_0_en_dof_row_done (access R/W1TC)
0x304 DMPAC_TOP__CFG_SLV__CP_INTD__INTD_CFG__INTD_CFG_enable_clr_reg_level_dmpac_out_0_1 — Enable Clear Register 1
  [27] ENABLE_LEVEL_DMPAC_OUT_0_EN_TDONE_8_CLR — Enable Clear for level_dmpac_out_0_en_tdone_8 (access R/W1TC)
  [26] ENABLE_LEVEL_DMPAC_OUT_0_EN_TDONE_7_CLR — Enable Clear for level_dmpac_out_0_en_tdone_7 (access R/W1TC)
  [25] ENABLE_LEVEL_DMPAC_OUT_0_EN_TDONE_1_CLR — Enable Clear for level_dmpac_out_0_en_tdone_1 (access R/W1TC)
  [24] ENABLE_LEVEL_DMPAC_OUT_0_EN_TDONE_0_CLR — Enable Clear for level_dmpac_out_0_en_tdone_0 (access R/W1TC)
  [19] ENABLE_LEVEL_DMPAC_OUT_0_EN_SPARE_PEND_1_L_CLR — Enable Clear for level_dmpac_out_0_en_spare_pend_1_l (access R/W1TC)
  [18] ENABLE_LEVEL_DMPAC_OUT_0_EN_SPARE_PEND_1_P_CLR — Enable Clear for level_dmpac_out_0_en_spare_pend_1_p (access R/W1TC)
  [17] ENABLE_LEVEL_DMPAC_OUT_0_EN_SPARE_PEND_0_L_CLR — Enable Clear for level_dmpac_out_0_en_spare_pend_0_l (access R/W1TC)
  [16] ENABLE_LEVEL_DMPAC_OUT_0_EN_SPARE_PEND_0_P_CLR — Enable Clear for level_dmpac_out_0_en_spare_pend_0_p (access R/W1TC)
  [9] ENABLE_LEVEL_DMPAC_OUT_0_EN_SPARE_DEC_1_CLR — Enable Clear for level_dmpac_out_0_en_spare_dec_1 (access R/W1TC)
  [8] ENABLE_LEVEL_DMPAC_OUT_0_EN_SPARE_DEC_0_CLR — Enable Clear for level_dmpac_out_0_en_spare_dec_0 (access R/W1TC)
  [n] ENABLE_LEVEL_DMPAC_OUT_0_EN_PIPE_DONE_{n}_CLR (n=0..3) — Enable Clear for level_dmpac_out_0_en_pipe_done_{n} (access R/W1TC)
0x308 DMPAC_TOP__CFG_SLV__CP_INTD__INTD_CFG__INTD_CFG_enable_clr_reg_level_dmpac_out_0_2 — Enable Clear Register 2
  [3] ENABLE_LEVEL_DMPAC_OUT_0_EN_WATCHDOGTIMER_ERR_8_CLR — Enable Clear for level_dmpac_out_0_en_watchdogtimer_err_8 (access R/W1TC)
  [2] ENABLE_LEVEL_DMPAC_OUT_0_EN_WATCHDOGTIMER_ERR_7_CLR — Enable Clear for level_dmpac_out_0_en_watchdogtimer_err_7 (access R/W1TC)
  [1] ENABLE_LEVEL_DMPAC_OUT_0_EN_WATCHDOGTIMER_ERR_1_CLR — Enable Clear for level_dmpac_out_0_en_watchdogtimer_err_1 (access R/W1TC)
  [0] ENABLE_LEVEL_DMPAC_OUT_0_EN_WATCHDOGTIMER_ERR_0_CLR — Enable Clear for level_dmpac_out_0_en_watchdogtimer_err_0 (access R/W1TC)
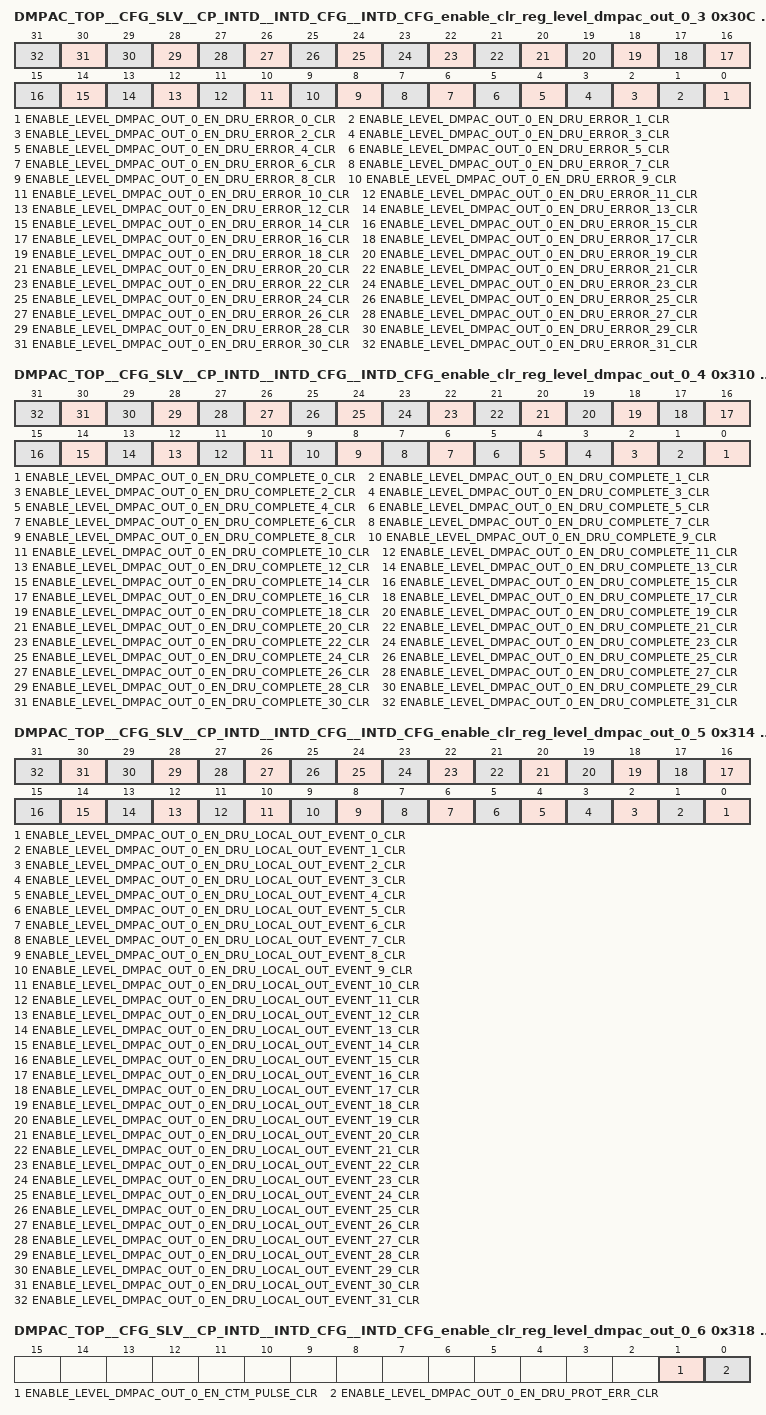
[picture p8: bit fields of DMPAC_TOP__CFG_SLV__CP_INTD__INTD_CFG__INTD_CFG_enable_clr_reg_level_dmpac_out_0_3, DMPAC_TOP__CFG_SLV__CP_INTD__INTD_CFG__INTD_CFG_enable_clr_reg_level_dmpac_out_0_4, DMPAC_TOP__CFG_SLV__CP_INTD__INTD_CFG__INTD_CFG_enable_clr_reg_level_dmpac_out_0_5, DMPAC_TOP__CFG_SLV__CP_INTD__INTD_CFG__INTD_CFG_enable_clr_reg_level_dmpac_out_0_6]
0x30C DMPAC_TOP__CFG_SLV__CP_INTD__INTD_CFG__INTD_CFG_enable_clr_reg_level_dmpac_out_0_3 — Enable Clear Register 3
  [n] ENABLE_LEVEL_DMPAC_OUT_0_EN_DRU_ERROR_{n}_CLR (n=0..31) — Enable Clear for level_dmpac_out_0_en_dru_error_{n} (access R/W1TC)
0x310 DMPAC_TOP__CFG_SLV__CP_INTD__INTD_CFG__INTD_CFG_enable_clr_reg_level_dmpac_out_0_4 — Enable Clear Register 4
  [n] ENABLE_LEVEL_DMPAC_OUT_0_EN_DRU_COMPLETE_{n}_CLR (n=0..31) — Enable Clear for level_dmpac_out_0_en_dru_complete_{n} (access R/W1TC)
0x314 DMPAC_TOP__CFG_SLV__CP_INTD__INTD_CFG__INTD_CFG_enable_clr_reg_level_dmpac_out_0_5 — Enable Clear Register 5
  [n] ENABLE_LEVEL_DMPAC_OUT_0_EN_DRU_LOCAL_OUT_EVENT_{n}_CLR (n=0..31) — Enable Clear for level_dmpac_out_0_en_dru_local_out_event_{n} (access R/W1TC)
0x318 DMPAC_TOP__CFG_SLV__CP_INTD__INTD_CFG__INTD_CFG_enable_clr_reg_level_dmpac_out_0_6 — Enable Clear Register 6
  [1] ENABLE_LEVEL_DMPAC_OUT_0_EN_CTM_PULSE_CLR — Enable Clear for level_dmpac_out_0_en_ctm_pulse (access R/W1TC)
  [0] ENABLE_LEVEL_DMPAC_OUT_0_EN_DRU_PROT_ERR_CLR — Enable Clear for level_dmpac_out_0_en_dru_prot_err (access R/W1TC)
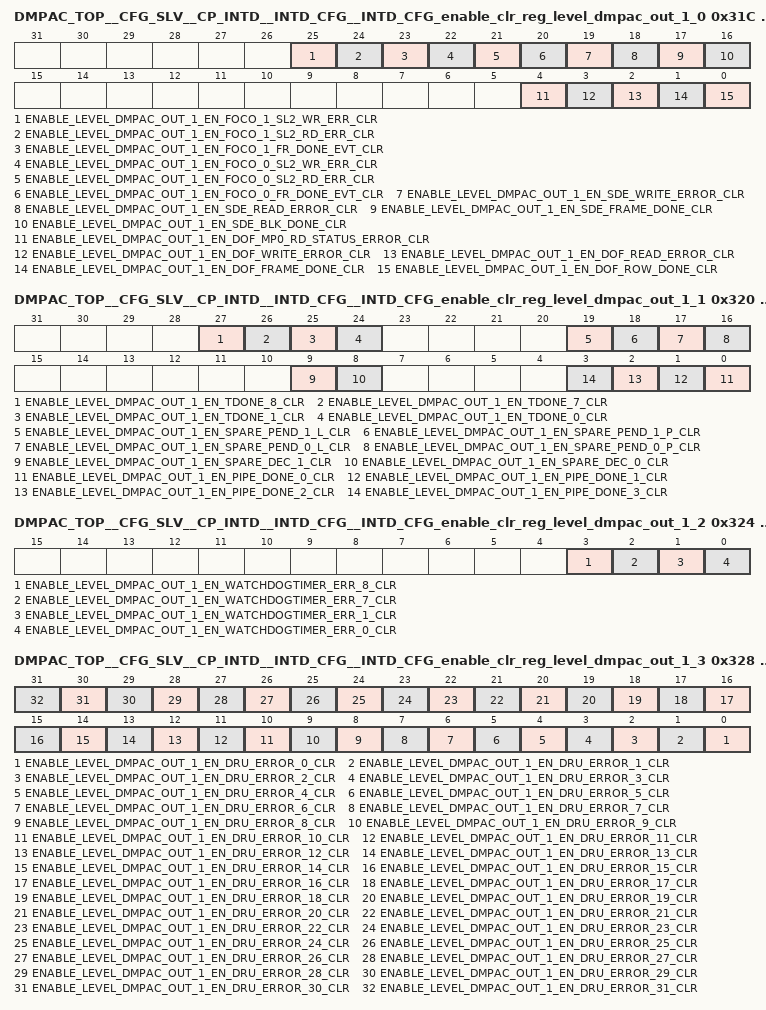
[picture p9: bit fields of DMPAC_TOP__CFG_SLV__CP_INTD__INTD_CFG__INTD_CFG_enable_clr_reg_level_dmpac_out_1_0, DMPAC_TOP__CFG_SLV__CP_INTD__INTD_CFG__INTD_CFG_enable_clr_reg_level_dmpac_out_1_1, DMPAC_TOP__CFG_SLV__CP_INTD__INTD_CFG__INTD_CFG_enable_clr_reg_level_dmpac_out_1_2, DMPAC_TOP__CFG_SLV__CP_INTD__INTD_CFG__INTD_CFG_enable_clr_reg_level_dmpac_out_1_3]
0x31C DMPAC_TOP__CFG_SLV__CP_INTD__INTD_CFG__INTD_CFG_enable_clr_reg_level_dmpac_out_1_0 — Enable Clear Register 7
  [25] ENABLE_LEVEL_DMPAC_OUT_1_EN_FOCO_1_SL2_WR_ERR_CLR — Enable Clear for level_dmpac_out_1_en_foco_1_sl2_wr_err (access R/W1TC)
  [24] ENABLE_LEVEL_DMPAC_OUT_1_EN_FOCO_1_SL2_RD_ERR_CLR — Enable Clear for level_dmpac_out_1_en_foco_1_sl2_rd_err (access R/W1TC)
  [23] ENABLE_LEVEL_DMPAC_OUT_1_EN_FOCO_1_FR_DONE_EVT_CLR — Enable Clear for level_dmpac_out_1_en_foco_1_fr_done_evt (access R/W1TC)
  [22] ENABLE_LEVEL_DMPAC_OUT_1_EN_FOCO_0_SL2_WR_ERR_CLR — Enable Clear for level_dmpac_out_1_en_foco_0_sl2_wr_err (access R/W1TC)
  [21] ENABLE_LEVEL_DMPAC_OUT_1_EN_FOCO_0_SL2_RD_ERR_CLR — Enable Clear for level_dmpac_out_1_en_foco_0_sl2_rd_err (access R/W1TC)
  [20] ENABLE_LEVEL_DMPAC_OUT_1_EN_FOCO_0_FR_DONE_EVT_CLR — Enable Clear for level_dmpac_out_1_en_foco_0_fr_done_evt (access R/W1TC)
  [19] ENABLE_LEVEL_DMPAC_OUT_1_EN_SDE_WRITE_ERROR_CLR — Enable Clear for level_dmpac_out_1_en_sde_write_error (access R/W1TC)
  [18] ENABLE_LEVEL_DMPAC_OUT_1_EN_SDE_READ_ERROR_CLR — Enable Clear for level_dmpac_out_1_en_sde_read_error (access R/W1TC)
  [17] ENABLE_LEVEL_DMPAC_OUT_1_EN_SDE_FRAME_DONE_CLR — Enable Clear for level_dmpac_out_1_en_sde_frame_done (access R/W1TC)
  [16] ENABLE_LEVEL_DMPAC_OUT_1_EN_SDE_BLK_DONE_CLR — Enable Clear for level_dmpac_out_1_en_sde_blk_done (access R/W1TC)
  [4] ENABLE_LEVEL_DMPAC_OUT_1_EN_DOF_MP0_RD_STATUS_ERROR_CLR — Enable Clear for level_dmpac_out_1_en_dof_mp0_rd_status_error (access R/W1TC)
  [3] ENABLE_LEVEL_DMPAC_OUT_1_EN_DOF_WRITE_ERROR_CLR — Enable Clear for level_dmpac_out_1_en_dof_write_error (access R/W1TC)
  [2] ENABLE_LEVEL_DMPAC_OUT_1_EN_DOF_READ_ERROR_CLR — Enable Clear for level_dmpac_out_1_en_dof_read_error (access R/W1TC)
  [1] ENABLE_LEVEL_DMPAC_OUT_1_EN_DOF_FRAME_DONE_CLR — Enable Clear for level_dmpac_out_1_en_dof_frame_done (access R/W1TC)
  [0] ENABLE_LEVEL_DMPAC_OUT_1_EN_DOF_ROW_DONE_CLR — Enable Clear for level_dmpac_out_1_en_dof_row_done (access R/W1TC)
0x320 DMPAC_TOP__CFG_SLV__CP_INTD__INTD_CFG__INTD_CFG_enable_clr_reg_level_dmpac_out_1_1 — Enable Clear Register 8
  [27] ENABLE_LEVEL_DMPAC_OUT_1_EN_TDONE_8_CLR — Enable Clear for level_dmpac_out_1_en_tdone_8 (access R/W1TC)
  [26] ENABLE_LEVEL_DMPAC_OUT_1_EN_TDONE_7_CLR — Enable Clear for level_dmpac_out_1_en_tdone_7 (access R/W1TC)
  [25] ENABLE_LEVEL_DMPAC_OUT_1_EN_TDONE_1_CLR — Enable Clear for level_dmpac_out_1_en_tdone_1 (access R/W1TC)
  [24] ENABLE_LEVEL_DMPAC_OUT_1_EN_TDONE_0_CLR — Enable Clear for level_dmpac_out_1_en_tdone_0 (access R/W1TC)
  [19] ENABLE_LEVEL_DMPAC_OUT_1_EN_SPARE_PEND_1_L_CLR — Enable Clear for level_dmpac_out_1_en_spare_pend_1_l (access R/W1TC)
  [18] ENABLE_LEVEL_DMPAC_OUT_1_EN_SPARE_PEND_1_P_CLR — Enable Clear for level_dmpac_out_1_en_spare_pend_1_p (access R/W1TC)
  [17] ENABLE_LEVEL_DMPAC_OUT_1_EN_SPARE_PEND_0_L_CLR — Enable Clear for level_dmpac_out_1_en_spare_pend_0_l (access R/W1TC)
  [16] ENABLE_LEVEL_DMPAC_OUT_1_EN_SPARE_PEND_0_P_CLR — Enable Clear for level_dmpac_out_1_en_spare_pend_0_p (access R/W1TC)
  [9] ENABLE_LEVEL_DMPAC_OUT_1_EN_SPARE_DEC_1_CLR — Enable Clear for level_dmpac_out_1_en_spare_dec_1 (access R/W1TC)
  [8] ENABLE_LEVEL_DMPAC_OUT_1_EN_SPARE_DEC_0_CLR — Enable Clear for level_dmpac_out_1_en_spare_dec_0 (access R/W1TC)
  [n] ENABLE_LEVEL_DMPAC_OUT_1_EN_PIPE_DONE_{n}_CLR (n=0..3) — Enable Clear for level_dmpac_out_1_en_pipe_done_{n} (access R/W1TC)
0x324 DMPAC_TOP__CFG_SLV__CP_INTD__INTD_CFG__INTD_CFG_enable_clr_reg_level_dmpac_out_1_2 — Enable Clear Register 9
  [3] ENABLE_LEVEL_DMPAC_OUT_1_EN_WATCHDOGTIMER_ERR_8_CLR — Enable Clear for level_dmpac_out_1_en_watchdogtimer_err_8 (access R/W1TC)
  [2] ENABLE_LEVEL_DMPAC_OUT_1_EN_WATCHDOGTIMER_ERR_7_CLR — Enable Clear for level_dmpac_out_1_en_watchdogtimer_err_7 (access R/W1TC)
  [1] ENABLE_LEVEL_DMPAC_OUT_1_EN_WATCHDOGTIMER_ERR_1_CLR — Enable Clear for level_dmpac_out_1_en_watchdogtimer_err_1 (access R/W1TC)
  [0] ENABLE_LEVEL_DMPAC_OUT_1_EN_WATCHDOGTIMER_ERR_0_CLR — Enable Clear for level_dmpac_out_1_en_watchdogtimer_err_0 (access R/W1TC)
0x328 DMPAC_TOP__CFG_SLV__CP_INTD__INTD_CFG__INTD_CFG_enable_clr_reg_level_dmpac_out_1_3 — Enable Clear Register 10
  [n] ENABLE_LEVEL_DMPAC_OUT_1_EN_DRU_ERROR_{n}_CLR (n=0..31) — Enable Clear for level_dmpac_out_1_en_dru_error_{n} (access R/W1TC)
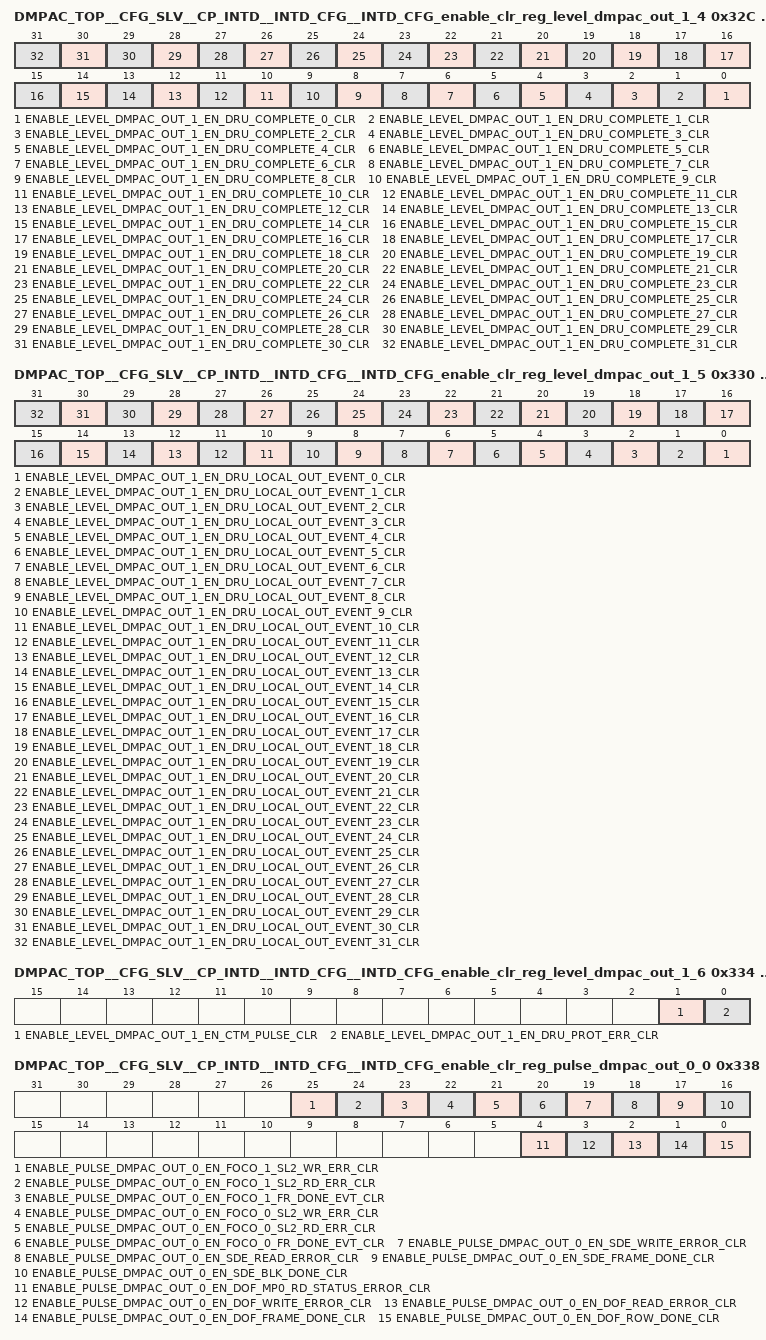
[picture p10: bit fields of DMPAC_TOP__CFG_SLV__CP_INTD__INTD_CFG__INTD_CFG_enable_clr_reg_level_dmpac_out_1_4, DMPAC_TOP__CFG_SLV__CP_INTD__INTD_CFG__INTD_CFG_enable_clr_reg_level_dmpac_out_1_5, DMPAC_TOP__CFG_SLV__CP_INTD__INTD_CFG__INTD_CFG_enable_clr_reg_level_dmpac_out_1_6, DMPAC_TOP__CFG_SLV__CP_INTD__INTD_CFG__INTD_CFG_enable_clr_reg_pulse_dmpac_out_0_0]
0x32C DMPAC_TOP__CFG_SLV__CP_INTD__INTD_CFG__INTD_CFG_enable_clr_reg_level_dmpac_out_1_4 — Enable Clear Register 11
  [n] ENABLE_LEVEL_DMPAC_OUT_1_EN_DRU_COMPLETE_{n}_CLR (n=0..31) — Enable Clear for level_dmpac_out_1_en_dru_complete_{n} (access R/W1TC)
0x330 DMPAC_TOP__CFG_SLV__CP_INTD__INTD_CFG__INTD_CFG_enable_clr_reg_level_dmpac_out_1_5 — Enable Clear Register 12
  [n] ENABLE_LEVEL_DMPAC_OUT_1_EN_DRU_LOCAL_OUT_EVENT_{n}_CLR (n=0..31) — Enable Clear for level_dmpac_out_1_en_dru_local_out_event_{n} (access R/W1TC)
0x334 DMPAC_TOP__CFG_SLV__CP_INTD__INTD_CFG__INTD_CFG_enable_clr_reg_level_dmpac_out_1_6 — Enable Clear Register 13
  [1] ENABLE_LEVEL_DMPAC_OUT_1_EN_CTM_PULSE_CLR — Enable Clear for level_dmpac_out_1_en_ctm_pulse (access R/W1TC)
  [0] ENABLE_LEVEL_DMPAC_OUT_1_EN_DRU_PROT_ERR_CLR — Enable Clear for level_dmpac_out_1_en_dru_prot_err (access R/W1TC)
0x338 DMPAC_TOP__CFG_SLV__CP_INTD__INTD_CFG__INTD_CFG_enable_clr_reg_pulse_dmpac_out_0_0 — Enable Clear Register 14
  [25] ENABLE_PULSE_DMPAC_OUT_0_EN_FOCO_1_SL2_WR_ERR_CLR — Enable Clear for pulse_dmpac_out_0_en_foco_1_sl2_wr_err (access R/W1TC)
  [24] ENABLE_PULSE_DMPAC_OUT_0_EN_FOCO_1_SL2_RD_ERR_CLR — Enable Clear for pulse_dmpac_out_0_en_foco_1_sl2_rd_err (access R/W1TC)
  [23] ENABLE_PULSE_DMPAC_OUT_0_EN_FOCO_1_FR_DONE_EVT_CLR — Enable Clear for pulse_dmpac_out_0_en_foco_1_fr_done_evt (access R/W1TC)
  [22] ENABLE_PULSE_DMPAC_OUT_0_EN_FOCO_0_SL2_WR_ERR_CLR — Enable Clear for pulse_dmpac_out_0_en_foco_0_sl2_wr_err (access R/W1TC)
  [21] ENABLE_PULSE_DMPAC_OUT_0_EN_FOCO_0_SL2_RD_ERR_CLR — Enable Clear for pulse_dmpac_out_0_en_foco_0_sl2_rd_err (access R/W1TC)
  [20] ENABLE_PULSE_DMPAC_OUT_0_EN_FOCO_0_FR_DONE_EVT_CLR — Enable Clear for pulse_dmpac_out_0_en_foco_0_fr_done_evt (access R/W1TC)
  [19] ENABLE_PULSE_DMPAC_OUT_0_EN_SDE_WRITE_ERROR_CLR — Enable Clear for pulse_dmpac_out_0_en_sde_write_error (access R/W1TC)
  [18] ENABLE_PULSE_DMPAC_OUT_0_EN_SDE_READ_ERROR_CLR — Enable Clear for pulse_dmpac_out_0_en_sde_read_error (access R/W1TC)
  [17] ENABLE_PULSE_DMPAC_OUT_0_EN_SDE_FRAME_DONE_CLR — Enable Clear for pulse_dmpac_out_0_en_sde_frame_done (access R/W1TC)
  [16] ENABLE_PULSE_DMPAC_OUT_0_EN_SDE_BLK_DONE_CLR — Enable Clear for pulse_dmpac_out_0_en_sde_blk_done (access R/W1TC)
  [4] ENABLE_PULSE_DMPAC_OUT_0_EN_DOF_MP0_RD_STATUS_ERROR_CLR — Enable Clear for pulse_dmpac_out_0_en_dof_mp0_rd_status_error (access R/W1TC)
  [3] ENABLE_PULSE_DMPAC_OUT_0_EN_DOF_WRITE_ERROR_CLR — Enable Clear for pulse_dmpac_out_0_en_dof_write_error (access R/W1TC)
  [2] ENABLE_PULSE_DMPAC_OUT_0_EN_DOF_READ_ERROR_CLR — Enable Clear for pulse_dmpac_out_0_en_dof_read_error (access R/W1TC)
  [1] ENABLE_PULSE_DMPAC_OUT_0_EN_DOF_FRAME_DONE_CLR — Enable Clear for pulse_dmpac_out_0_en_dof_frame_done (access R/W1TC)
  [0] ENABLE_PULSE_DMPAC_OUT_0_EN_DOF_ROW_DONE_CLR — Enable Clear for pulse_dmpac_out_0_en_dof_row_done (access R/W1TC)
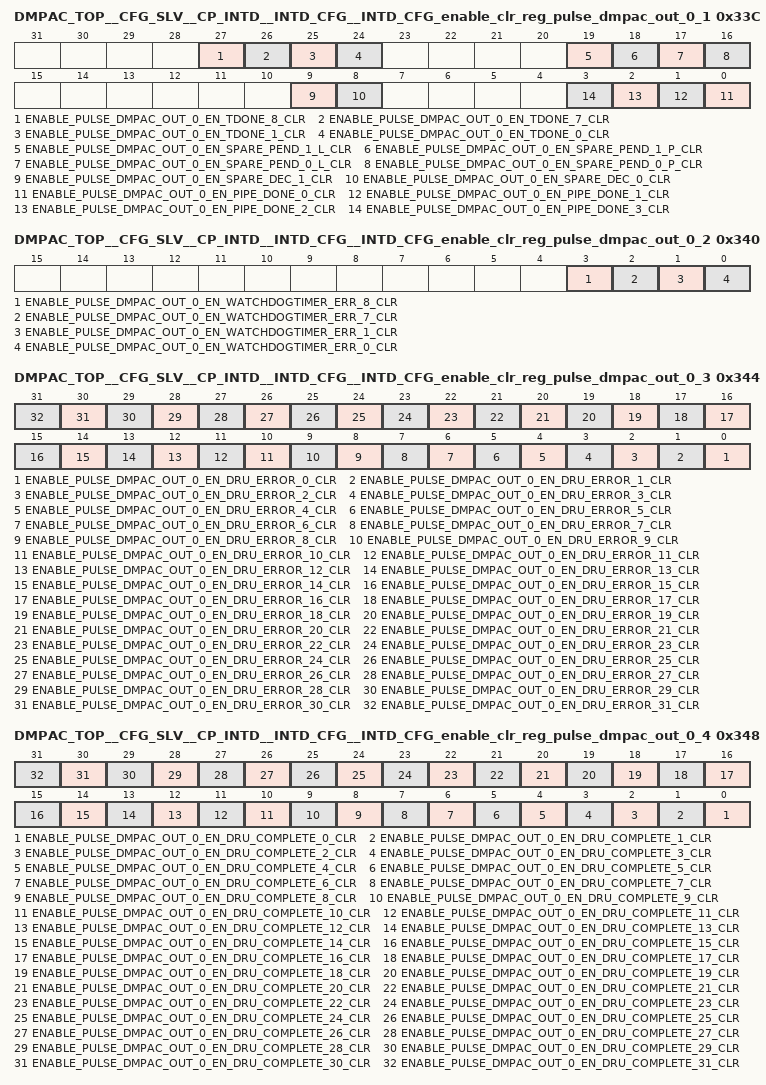
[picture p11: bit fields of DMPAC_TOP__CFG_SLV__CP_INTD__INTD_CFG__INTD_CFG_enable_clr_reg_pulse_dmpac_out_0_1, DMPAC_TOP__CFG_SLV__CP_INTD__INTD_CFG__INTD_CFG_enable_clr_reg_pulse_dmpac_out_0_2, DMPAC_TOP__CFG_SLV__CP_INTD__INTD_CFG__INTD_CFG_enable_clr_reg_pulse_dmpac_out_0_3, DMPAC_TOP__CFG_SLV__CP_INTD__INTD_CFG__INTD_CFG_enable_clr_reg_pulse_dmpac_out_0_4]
0x33C DMPAC_TOP__CFG_SLV__CP_INTD__INTD_CFG__INTD_CFG_enable_clr_reg_pulse_dmpac_out_0_1 — Enable Clear Register 15
  [27] ENABLE_PULSE_DMPAC_OUT_0_EN_TDONE_8_CLR — Enable Clear for pulse_dmpac_out_0_en_tdone_8 (access R/W1TC)
  [26] ENABLE_PULSE_DMPAC_OUT_0_EN_TDONE_7_CLR — Enable Clear for pulse_dmpac_out_0_en_tdone_7 (access R/W1TC)
  [25] ENABLE_PULSE_DMPAC_OUT_0_EN_TDONE_1_CLR — Enable Clear for pulse_dmpac_out_0_en_tdone_1 (access R/W1TC)
  [24] ENABLE_PULSE_DMPAC_OUT_0_EN_TDONE_0_CLR — Enable Clear for pulse_dmpac_out_0_en_tdone_0 (access R/W1TC)
  [19] ENABLE_PULSE_DMPAC_OUT_0_EN_SPARE_PEND_1_L_CLR — Enable Clear for pulse_dmpac_out_0_en_spare_pend_1_l (access R/W1TC)
  [18] ENABLE_PULSE_DMPAC_OUT_0_EN_SPARE_PEND_1_P_CLR — Enable Clear for pulse_dmpac_out_0_en_spare_pend_1_p (access R/W1TC)
  [17] ENABLE_PULSE_DMPAC_OUT_0_EN_SPARE_PEND_0_L_CLR — Enable Clear for pulse_dmpac_out_0_en_spare_pend_0_l (access R/W1TC)
  [16] ENABLE_PULSE_DMPAC_OUT_0_EN_SPARE_PEND_0_P_CLR — Enable Clear for pulse_dmpac_out_0_en_spare_pend_0_p (access R/W1TC)
  [9] ENABLE_PULSE_DMPAC_OUT_0_EN_SPARE_DEC_1_CLR — Enable Clear for pulse_dmpac_out_0_en_spare_dec_1 (access R/W1TC)
  [8] ENABLE_PULSE_DMPAC_OUT_0_EN_SPARE_DEC_0_CLR — Enable Clear for pulse_dmpac_out_0_en_spare_dec_0 (access R/W1TC)
  [n] ENABLE_PULSE_DMPAC_OUT_0_EN_PIPE_DONE_{n}_CLR (n=0..3) — Enable Clear for pulse_dmpac_out_0_en_pipe_done_{n} (access R/W1TC)
0x340 DMPAC_TOP__CFG_SLV__CP_INTD__INTD_CFG__INTD_CFG_enable_clr_reg_pulse_dmpac_out_0_2 — Enable Clear Register 16
  [3] ENABLE_PULSE_DMPAC_OUT_0_EN_WATCHDOGTIMER_ERR_8_CLR — Enable Clear for pulse_dmpac_out_0_en_watchdogtimer_err_8 (access R/W1TC)
  [2] ENABLE_PULSE_DMPAC_OUT_0_EN_WATCHDOGTIMER_ERR_7_CLR — Enable Clear for pulse_dmpac_out_0_en_watchdogtimer_err_7 (access R/W1TC)
  [1] ENABLE_PULSE_DMPAC_OUT_0_EN_WATCHDOGTIMER_ERR_1_CLR — Enable Clear for pulse_dmpac_out_0_en_watchdogtimer_err_1 (access R/W1TC)
  [0] ENABLE_PULSE_DMPAC_OUT_0_EN_WATCHDOGTIMER_ERR_0_CLR — Enable Clear for pulse_dmpac_out_0_en_watchdogtimer_err_0 (access R/W1TC)
0x344 DMPAC_TOP__CFG_SLV__CP_INTD__INTD_CFG__INTD_CFG_enable_clr_reg_pulse_dmpac_out_0_3 — Enable Clear Register 17
  [n] ENABLE_PULSE_DMPAC_OUT_0_EN_DRU_ERROR_{n}_CLR (n=0..31) — Enable Clear for pulse_dmpac_out_0_en_dru_error_{n} (access R/W1TC)
0x348 DMPAC_TOP__CFG_SLV__CP_INTD__INTD_CFG__INTD_CFG_enable_clr_reg_pulse_dmpac_out_0_4 — Enable Clear Register 18
  [n] ENABLE_PULSE_DMPAC_OUT_0_EN_DRU_COMPLETE_{n}_CLR (n=0..31) — Enable Clear for pulse_dmpac_out_0_en_dru_complete_{n} (access R/W1TC)
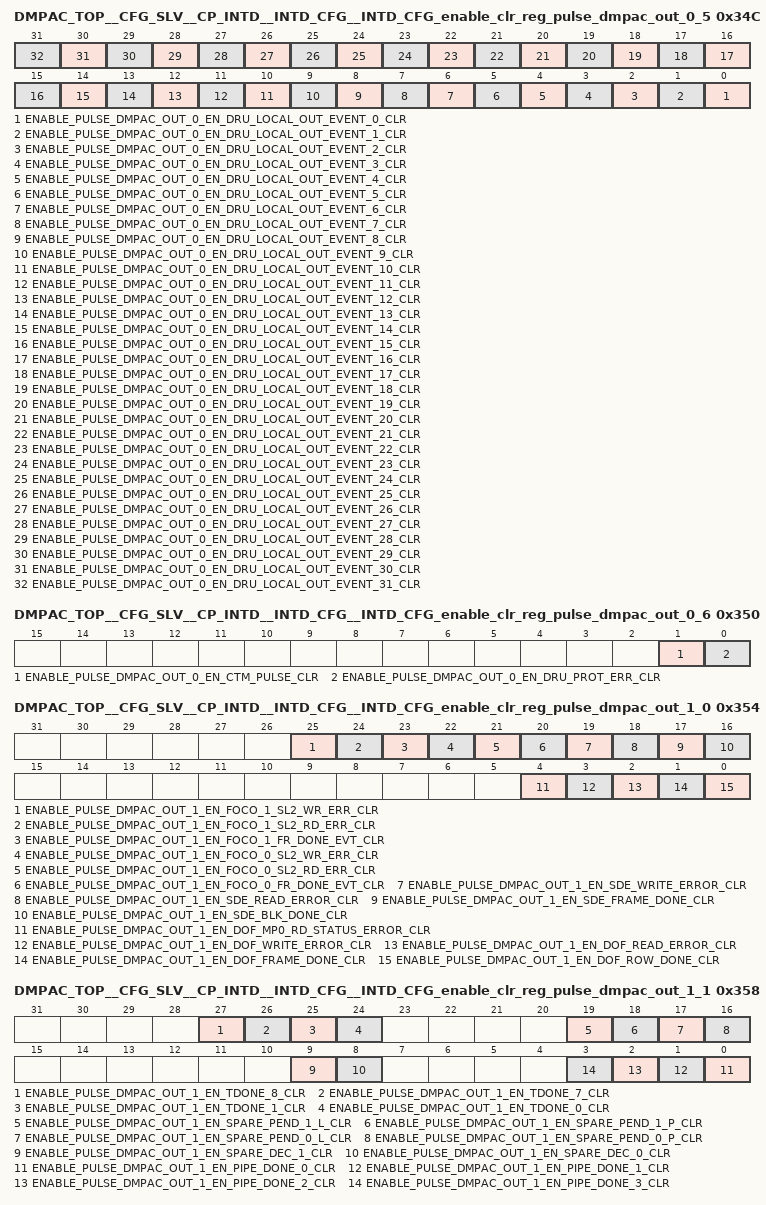
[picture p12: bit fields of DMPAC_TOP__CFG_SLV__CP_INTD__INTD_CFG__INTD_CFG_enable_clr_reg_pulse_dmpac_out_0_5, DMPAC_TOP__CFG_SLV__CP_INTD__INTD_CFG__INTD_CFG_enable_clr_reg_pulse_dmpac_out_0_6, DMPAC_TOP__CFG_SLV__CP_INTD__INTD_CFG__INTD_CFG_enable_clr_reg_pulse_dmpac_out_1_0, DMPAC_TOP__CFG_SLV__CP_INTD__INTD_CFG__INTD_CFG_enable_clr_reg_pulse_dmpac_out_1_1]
0x34C DMPAC_TOP__CFG_SLV__CP_INTD__INTD_CFG__INTD_CFG_enable_clr_reg_pulse_dmpac_out_0_5 — Enable Clear Register 19
  [n] ENABLE_PULSE_DMPAC_OUT_0_EN_DRU_LOCAL_OUT_EVENT_{n}_CLR (n=0..31) — Enable Clear for pulse_dmpac_out_0_en_dru_local_out_event_{n} (access R/W1TC)
0x350 DMPAC_TOP__CFG_SLV__CP_INTD__INTD_CFG__INTD_CFG_enable_clr_reg_pulse_dmpac_out_0_6 — Enable Clear Register 20
  [1] ENABLE_PULSE_DMPAC_OUT_0_EN_CTM_PULSE_CLR — Enable Clear for pulse_dmpac_out_0_en_ctm_pulse (access R/W1TC)
  [0] ENABLE_PULSE_DMPAC_OUT_0_EN_DRU_PROT_ERR_CLR — Enable Clear for pulse_dmpac_out_0_en_dru_prot_err (access R/W1TC)
0x354 DMPAC_TOP__CFG_SLV__CP_INTD__INTD_CFG__INTD_CFG_enable_clr_reg_pulse_dmpac_out_1_0 — Enable Clear Register 21
  [25] ENABLE_PULSE_DMPAC_OUT_1_EN_FOCO_1_SL2_WR_ERR_CLR — Enable Clear for pulse_dmpac_out_1_en_foco_1_sl2_wr_err (access R/W1TC)
  [24] ENABLE_PULSE_DMPAC_OUT_1_EN_FOCO_1_SL2_RD_ERR_CLR — Enable Clear for pulse_dmpac_out_1_en_foco_1_sl2_rd_err (access R/W1TC)
  [23] ENABLE_PULSE_DMPAC_OUT_1_EN_FOCO_1_FR_DONE_EVT_CLR — Enable Clear for pulse_dmpac_out_1_en_foco_1_fr_done_evt (access R/W1TC)
  [22] ENABLE_PULSE_DMPAC_OUT_1_EN_FOCO_0_SL2_WR_ERR_CLR — Enable Clear for pulse_dmpac_out_1_en_foco_0_sl2_wr_err (access R/W1TC)
  [21] ENABLE_PULSE_DMPAC_OUT_1_EN_FOCO_0_SL2_RD_ERR_CLR — Enable Clear for pulse_dmpac_out_1_en_foco_0_sl2_rd_err (access R/W1TC)
  [20] ENABLE_PULSE_DMPAC_OUT_1_EN_FOCO_0_FR_DONE_EVT_CLR — Enable Clear for pulse_dmpac_out_1_en_foco_0_fr_done_evt (access R/W1TC)
  [19] ENABLE_PULSE_DMPAC_OUT_1_EN_SDE_WRITE_ERROR_CLR — Enable Clear for pulse_dmpac_out_1_en_sde_write_error (access R/W1TC)
  [18] ENABLE_PULSE_DMPAC_OUT_1_EN_SDE_READ_ERROR_CLR — Enable Clear for pulse_dmpac_out_1_en_sde_read_error (access R/W1TC)
  [17] ENABLE_PULSE_DMPAC_OUT_1_EN_SDE_FRAME_DONE_CLR — Enable Clear for pulse_dmpac_out_1_en_sde_frame_done (access R/W1TC)
  [16] ENABLE_PULSE_DMPAC_OUT_1_EN_SDE_BLK_DONE_CLR — Enable Clear for pulse_dmpac_out_1_en_sde_blk_done (access R/W1TC)
  [4] ENABLE_PULSE_DMPAC_OUT_1_EN_DOF_MP0_RD_STATUS_ERROR_CLR — Enable Clear for pulse_dmpac_out_1_en_dof_mp0_rd_status_error (access R/W1TC)
  [3] ENABLE_PULSE_DMPAC_OUT_1_EN_DOF_WRITE_ERROR_CLR — Enable Clear for pulse_dmpac_out_1_en_dof_write_error (access R/W1TC)
  [2] ENABLE_PULSE_DMPAC_OUT_1_EN_DOF_READ_ERROR_CLR — Enable Clear for pulse_dmpac_out_1_en_dof_read_error (access R/W1TC)
  [1] ENABLE_PULSE_DMPAC_OUT_1_EN_DOF_FRAME_DONE_CLR — Enable Clear for pulse_dmpac_out_1_en_dof_frame_done (access R/W1TC)
  [0] ENABLE_PULSE_DMPAC_OUT_1_EN_DOF_ROW_DONE_CLR — Enable Clear for pulse_dmpac_out_1_en_dof_row_done (access R/W1TC)
0x358 DMPAC_TOP__CFG_SLV__CP_INTD__INTD_CFG__INTD_CFG_enable_clr_reg_pulse_dmpac_out_1_1 — Enable Clear Register 22
  [27] ENABLE_PULSE_DMPAC_OUT_1_EN_TDONE_8_CLR — Enable Clear for pulse_dmpac_out_1_en_tdone_8 (access R/W1TC)
  [26] ENABLE_PULSE_DMPAC_OUT_1_EN_TDONE_7_CLR — Enable Clear for pulse_dmpac_out_1_en_tdone_7 (access R/W1TC)
  [25] ENABLE_PULSE_DMPAC_OUT_1_EN_TDONE_1_CLR — Enable Clear for pulse_dmpac_out_1_en_tdone_1 (access R/W1TC)
  [24] ENABLE_PULSE_DMPAC_OUT_1_EN_TDONE_0_CLR — Enable Clear for pulse_dmpac_out_1_en_tdone_0 (access R/W1TC)
  [19] ENABLE_PULSE_DMPAC_OUT_1_EN_SPARE_PEND_1_L_CLR — Enable Clear for pulse_dmpac_out_1_en_spare_pend_1_l (access R/W1TC)
  [18] ENABLE_PULSE_DMPAC_OUT_1_EN_SPARE_PEND_1_P_CLR — Enable Clear for pulse_dmpac_out_1_en_spare_pend_1_p (access R/W1TC)
  [17] ENABLE_PULSE_DMPAC_OUT_1_EN_SPARE_PEND_0_L_CLR — Enable Clear for pulse_dmpac_out_1_en_spare_pend_0_l (access R/W1TC)
  [16] ENABLE_PULSE_DMPAC_OUT_1_EN_SPARE_PEND_0_P_CLR — Enable Clear for pulse_dmpac_out_1_en_spare_pend_0_p (access R/W1TC)
  [9] ENABLE_PULSE_DMPAC_OUT_1_EN_SPARE_DEC_1_CLR — Enable Clear for pulse_dmpac_out_1_en_spare_dec_1 (access R/W1TC)
  [8] ENABLE_PULSE_DMPAC_OUT_1_EN_SPARE_DEC_0_CLR — Enable Clear for pulse_dmpac_out_1_en_spare_dec_0 (access R/W1TC)
  [n] ENABLE_PULSE_DMPAC_OUT_1_EN_PIPE_DONE_{n}_CLR (n=0..3) — Enable Clear for pulse_dmpac_out_1_en_pipe_done_{n} (access R/W1TC)
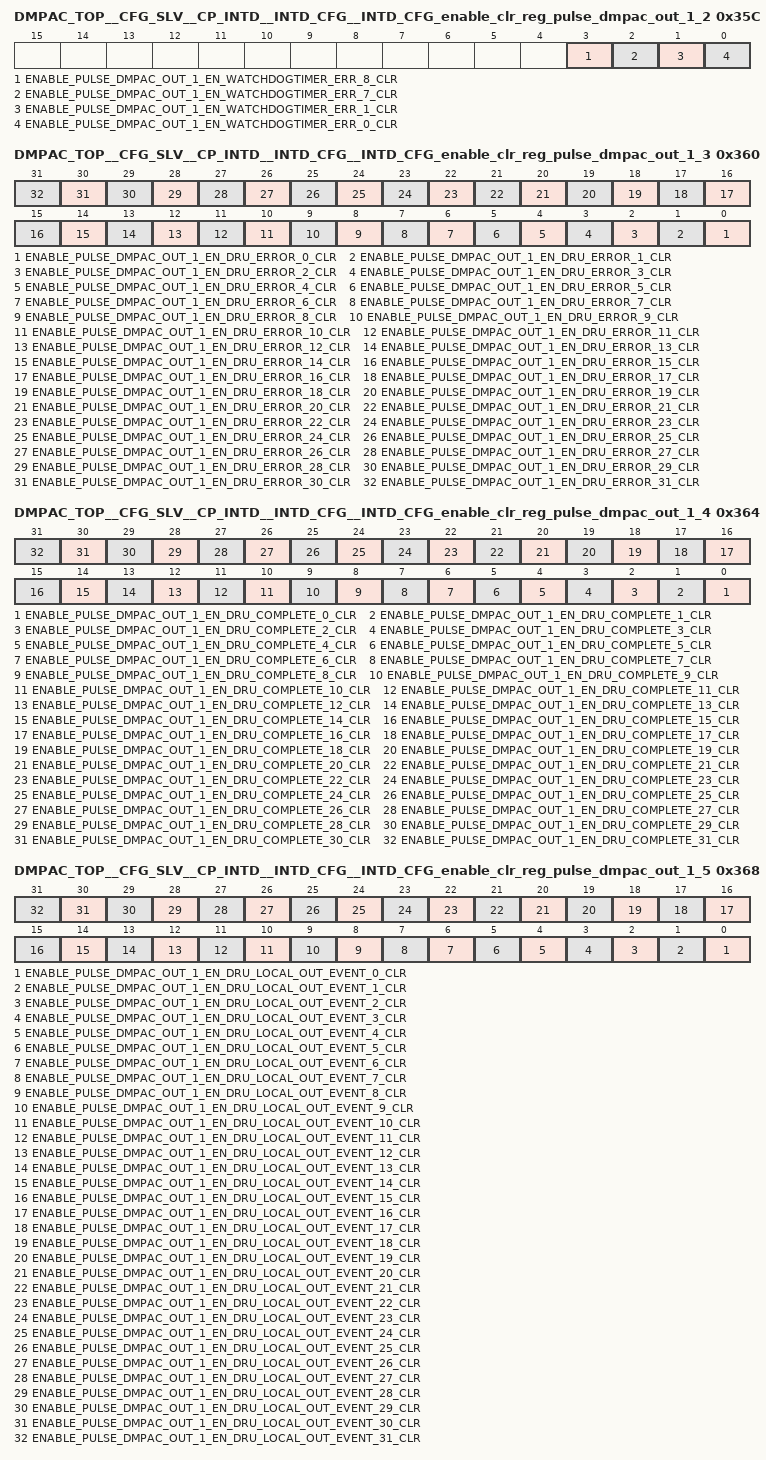
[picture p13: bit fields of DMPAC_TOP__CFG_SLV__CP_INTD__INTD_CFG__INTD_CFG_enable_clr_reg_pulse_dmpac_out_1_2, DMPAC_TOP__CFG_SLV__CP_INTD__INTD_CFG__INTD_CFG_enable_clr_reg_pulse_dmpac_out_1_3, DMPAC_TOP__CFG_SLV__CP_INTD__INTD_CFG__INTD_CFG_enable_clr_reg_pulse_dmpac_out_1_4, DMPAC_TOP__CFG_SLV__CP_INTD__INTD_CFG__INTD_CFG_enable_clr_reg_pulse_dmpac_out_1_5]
0x35C DMPAC_TOP__CFG_SLV__CP_INTD__INTD_CFG__INTD_CFG_enable_clr_reg_pulse_dmpac_out_1_2 — Enable Clear Register 23
  [3] ENABLE_PULSE_DMPAC_OUT_1_EN_WATCHDOGTIMER_ERR_8_CLR — Enable Clear for pulse_dmpac_out_1_en_watchdogtimer_err_8 (access R/W1TC)
  [2] ENABLE_PULSE_DMPAC_OUT_1_EN_WATCHDOGTIMER_ERR_7_CLR — Enable Clear for pulse_dmpac_out_1_en_watchdogtimer_err_7 (access R/W1TC)
  [1] ENABLE_PULSE_DMPAC_OUT_1_EN_WATCHDOGTIMER_ERR_1_CLR — Enable Clear for pulse_dmpac_out_1_en_watchdogtimer_err_1 (access R/W1TC)
  [0] ENABLE_PULSE_DMPAC_OUT_1_EN_WATCHDOGTIMER_ERR_0_CLR — Enable Clear for pulse_dmpac_out_1_en_watchdogtimer_err_0 (access R/W1TC)
0x360 DMPAC_TOP__CFG_SLV__CP_INTD__INTD_CFG__INTD_CFG_enable_clr_reg_pulse_dmpac_out_1_3 — Enable Clear Register 24
  [n] ENABLE_PULSE_DMPAC_OUT_1_EN_DRU_ERROR_{n}_CLR (n=0..31) — Enable Clear for pulse_dmpac_out_1_en_dru_error_{n} (access R/W1TC)
0x364 DMPAC_TOP__CFG_SLV__CP_INTD__INTD_CFG__INTD_CFG_enable_clr_reg_pulse_dmpac_out_1_4 — Enable Clear Register 25
  [n] ENABLE_PULSE_DMPAC_OUT_1_EN_DRU_COMPLETE_{n}_CLR (n=0..31) — Enable Clear for pulse_dmpac_out_1_en_dru_complete_{n} (access R/W1TC)
0x368 DMPAC_TOP__CFG_SLV__CP_INTD__INTD_CFG__INTD_CFG_enable_clr_reg_pulse_dmpac_out_1_5 — Enable Clear Register 26
  [n] ENABLE_PULSE_DMPAC_OUT_1_EN_DRU_LOCAL_OUT_EVENT_{n}_CLR (n=0..31) — Enable Clear for pulse_dmpac_out_1_en_dru_local_out_event_{n} (access R/W1TC)
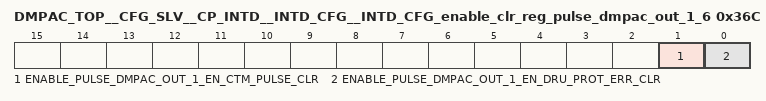
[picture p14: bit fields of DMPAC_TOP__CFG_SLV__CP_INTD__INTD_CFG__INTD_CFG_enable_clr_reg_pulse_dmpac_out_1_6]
0x36C DMPAC_TOP__CFG_SLV__CP_INTD__INTD_CFG__INTD_CFG_enable_clr_reg_pulse_dmpac_out_1_6 — Enable Clear Register 27
  [1] ENABLE_PULSE_DMPAC_OUT_1_EN_CTM_PULSE_CLR — Enable Clear for pulse_dmpac_out_1_en_ctm_pulse (access R/W1TC)
  [0] ENABLE_PULSE_DMPAC_OUT_1_EN_DRU_PROT_ERR_CLR — Enable Clear for pulse_dmpac_out_1_en_dru_prot_err (access R/W1TC)
